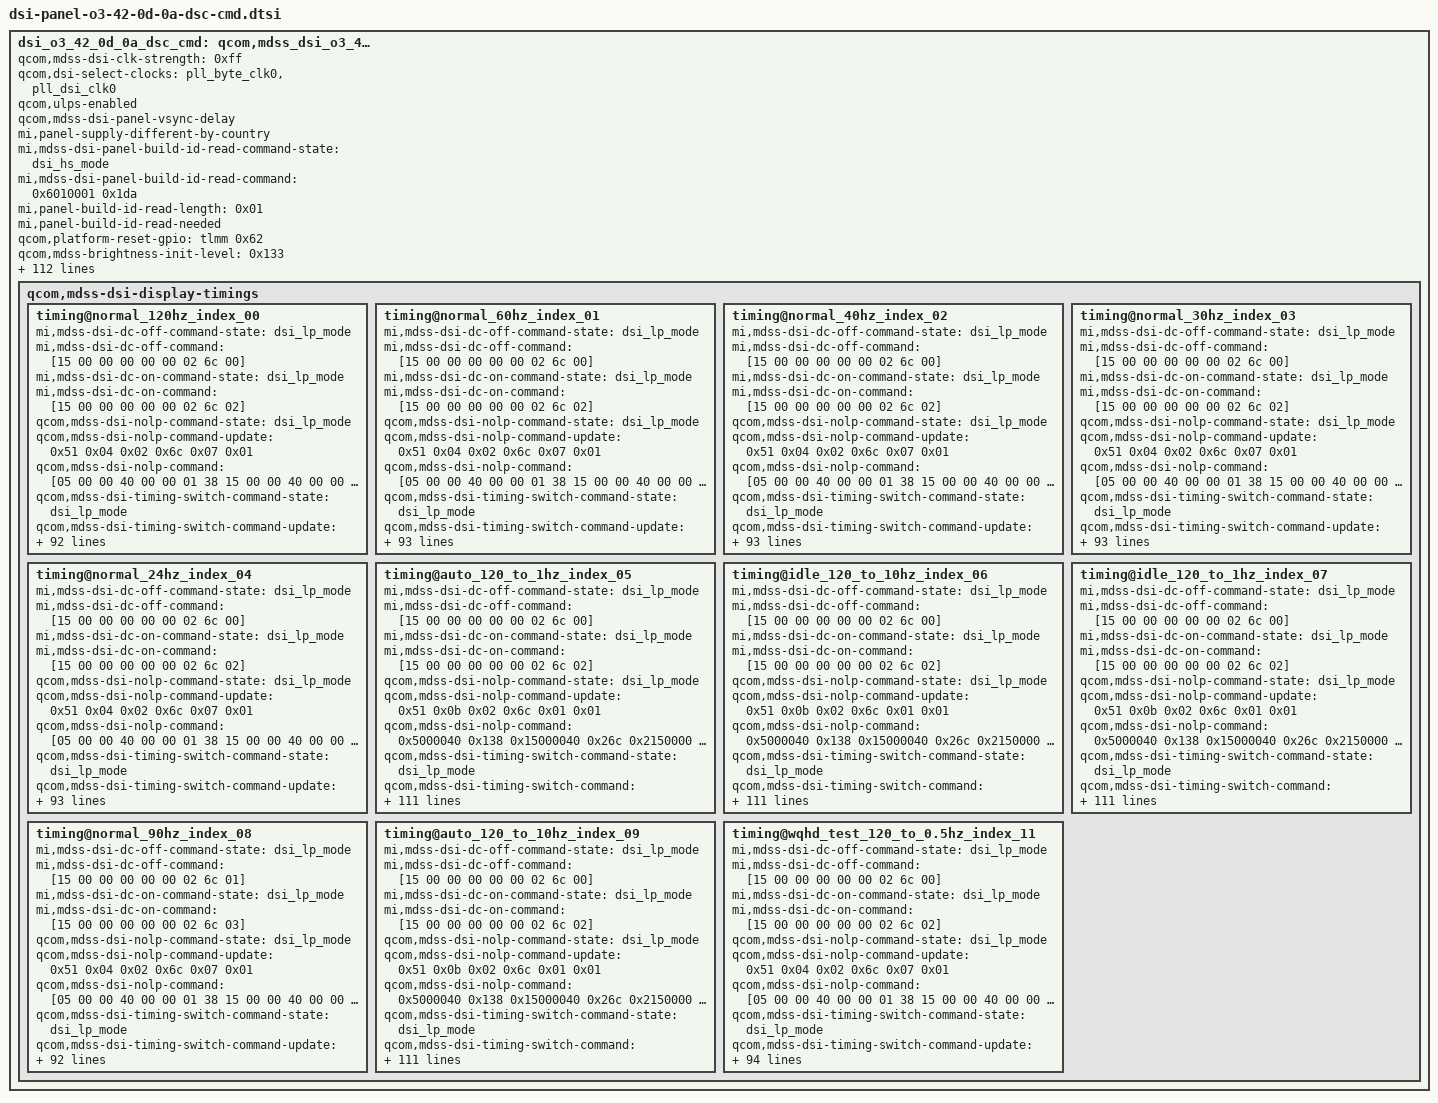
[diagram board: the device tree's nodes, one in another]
// SPDX-License-Identifier: BSD-3-Clause
/*
 * Copyright (c) 2023-2024 Qualcomm Innovation Center, Inc. All rights reserved.
 * Copyright (c) 2025 The LineageOS Project
 */

dsi_o3_42_0d_0a_dsc_cmd: qcom,mdss_dsi_o3_42_0d_0a_dsc_cmd {
	qcom,mdss-dsi-clk-strength = <0xff>;
	qcom,dsi-select-clocks = "pll_byte_clk0", "pll_dsi_clk0";
	qcom,ulps-enabled;
	qcom,mdss-dsi-panel-vsync-delay;
	mi,panel-supply-different-by-country;
	mi,mdss-dsi-panel-build-id-read-command-state = "dsi_hs_mode";
	mi,mdss-dsi-panel-build-id-read-command = <0x6010001 0x1da>;
	mi,panel-build-id-read-length = <0x01>;
	mi,panel-build-id-read-needed;
	qcom,platform-reset-gpio = <&tlmm 0x62 0x00>;
	qcom,mdss-brightness-init-level = <0x133>;
	qcom,mdss-brightness-max-level = <0x1fff>;
	qcom,bl-dsc-cmd-state = "dsi_hs_mode";
	qcom,mdss-dsi-bl-max-level = <0x1fff>;
	qcom,mdss-dsi-bl-min-level = <0x19>;
	qcom,mdss-dsi-bl-pmic-control-type = "bl_ctrl_dcs";
	qcom,panel-global-supply-entries = <&dsi_panel_pwr_supply_O3GL>;
	qcom,panel-supply-entries = <&dsi_panel_pwr_supply_O3>;
	qcom,mdss-disable-cesta-hw-sleep;
	mi,ddic-round-corner-enabled;
	mi,dc-feature-enabled;
	mi,doze-lbm-dbv-level = <0x12>;
	mi,doze-hbm-dbv-level = <0xcf>;
	mi,mdss-dsi-panel-flatmode-on-status-value = <0x71>;
	mi,mdss-dsi-panel-flatmode-status-read-length = <0x01>;
	mi,mdss-dsi-panel-flatmode-status-command-state = "dsi_hs_mode";
	mi,mdss-dsi-panel-flatmode-status-command = <0x6010001 0x1d5>;
	mi,mdss-dsi-panel-flatmode-status-offset-command-state = "dsi_hs_mode";
	mi,mdss-dsi-panel-flatmode-status-offset-command = [39 00 00 00 00 00 03 f0 aa 11];
	mi,flatmode-status-check-enabled;
	mi,mdss-fac-brightness-max-level = <0xaab>;
	mi,mdss-dsi-fac-bl-max-level = <0xaab>;
	qcom,mdss-dsi-panel-status-read-length = <0x01 0x03>;
	qcom,mdss-dsi-panel-status-value = <0x08 0x12 0x00 0x00>;
	mi,mdss-dsi-panel-status-after-command-state = "dsi_lp_mode";
	mi,mdss-dsi-panel-status-offset-command-state = "dsi_lp_mode";
	qcom,mdss-dsi-panel-status-command-state = "dsi_lp_mode";
	mi,mdss-dsi-panel-status-after-command = <0x39000000 0x3ff 0x5a003900 0x00 0x3f0aa00>;
	qcom,mdss-dsi-panel-status-command = <0x6010000 0x1f9 0x6010000 0x170>;
	mi,mdss-dsi-panel-status-offset-command = [39 00 00 00 00 00 03 ff 5a 82 39 00 00 00 00 00 02 65 01];
	qcom,mdss-dsi-panel-status-check-mode = "reg_read";
	mi,mdss-dsi-panel-status-check-interval = <0x1388>;
	qcom,esd-aod-check-enabled;
	qcom,esd-check-enabled;
	mi,mdss-dsi-panel-cell-id-read-length = <0x0d>;
	mi,mdss-dsi-panel-cell-id-read-command-state = "dsi_hs_mode";
	mi,mdss-dsi-panel-cell-id-read-command = <0x6010001 0x15a>;
	mi,mdss-dsi-panel-wp-read-length = <0x08>;
	mi,mdss-dsi-panel-wp-read-command-state = "dsi_hs_mode";
	mi,mdss-dsi-panel-wp-read-command = <0x6010001 0x15c>;
	qcom,spr-pentile-pack-type = "RG-BG Type A";
	qcom,spr-pack-type = "pentile";
	mi,esd-err-irq-gpio-flag = <0x2004>;
	mi,esd-err-irq-gpio = <&tlmm 0x57 0x2004>;
	mi,need-update-gamma-befor-init;
	mi,max-brightness-clone = <0x3fff>;
	mi,panel-on-dimming-delay = <0x78>;
	mi,panel-id = <0x4f33 0x420d0a>;
	qcom,mdss-dsi-dma-schedule-window = <0x32>;
	qcom,mdss-dsi-dma-schedule-line = <0x01>;
	qcom,bl-update-flag = "delay_until_first_frame";
	qcom,mdss-dsi-bl-inverted-dbv;
	qcom,mdss-dsi-panel-blackness-level = <0xc9e>;
	qcom,mdss-dsi-panel-peak-brightness = <0x1e84800>;
	qcom,mdss-dsi-panel-hdr-color-primaries = <0x38a4 0x3c8c 0x7d00 0x4268 0x3c8c 0x7530 0x1f40 0xbb8>;
	qcom,mdss-dsi-panel-hdr-enabled;
	qcom,mdss-dsi-lp11-init;
	qcom,mdss-dsi-tx-eot-append;
	qcom,mdss-dsi-te-using-te-pin;
	qcom,mdss-dsi-te-check-enable;
	qcom,mdss-dsi-te-dcs-command = <0x01>;
	qcom,mdss-dsi-wr-mem-continue = <0x3c>;
	qcom,mdss-dsi-wr-mem-start = <0x2c>;
	qcom,mdss-dsi-te-pin-select = <0x01>;
	qcom,mdss-pan-physical-height-dimension = <0x5c1>;
	qcom,mdss-pan-physical-width-dimension = <0x297>;
	qcom,mdss-dsi-reset-sequence = <0x00 0x0f 0x01 0x19>;
	qcom,mdss-dsi-mdp-trigger = "none";
	qcom,mdss-dsi-dma-trigger = "trigger_sw";
	qcom,mdss-dsi-lane-3-state;
	qcom,mdss-dsi-lane-2-state;
	qcom,mdss-dsi-lane-1-state;
	qcom,mdss-dsi-lane-0-state;
	qcom,mdss-dsi-bllp-power-mode;
	qcom,mdss-dsi-bllp-eof-power-mode;
	qcom,mdss-dsi-lane-map = "lane_map_0123";
	qcom,mdss-dsi-traffic-mode = "burst_mode";
	qcom,dsi-phy-num = <0x00>;
	qcom,dsi-ctrl-num = <0x00>;
	qcom,mdss-dsi-border-color = <0x00>;
	qcom,mdss-dsi-underflow-color = <0xff>;
	qcom,mdss-dsi-color-order = "rgb_swap_rgb";
	qcom,mdss-dsi-bpp = <0x1e>;
	qcom,mdss-dsi-stream = <0x00>;
	qcom,mdss-dsi-virtual-channel-id = <0x00>;
	qcom,mdss-dsi-panel-type = "dsi_cmd_mode";
	qcom,mdss-dsi-panel-name = "xiaomi o3 42 0d 0a cmd mode dsc dsi panel";

	qcom,mdss-dsi-display-timings {

		timing@normal_120hz_index_00 {
			mi,mdss-dsi-dc-off-command-state = "dsi_lp_mode";
			mi,mdss-dsi-dc-off-command = [15 00 00 00 00 00 02 6c 00];
			mi,mdss-dsi-dc-on-command-state = "dsi_lp_mode";
			mi,mdss-dsi-dc-on-command = [15 00 00 00 00 00 02 6c 02];
			qcom,mdss-dsi-nolp-command-state = "dsi_lp_mode";
			qcom,mdss-dsi-nolp-command-update = <0x51 0x04 0x02 0x6c 0x07 0x01>;
			qcom,mdss-dsi-nolp-command = [05 00 00 40 00 00 01 38 15 00 00 40 00 00 02 75 00 39 00 00 40 00 00 03 f0 aa 1b 15 00 00 40 00 00 02 d0 00 39 00 00 40 00 00 03 51 00 00 39 00 00 40 00 00 03 f0 aa 10 15 00 00 00 09 00 02 cf 16 15 00 00 40 00 00 02 6c 02 15 00 00 40 00 00 02 71 00 39 00 00 00 00 00 03 f0 aa 00];
			qcom,mdss-dsi-timing-switch-command-state = "dsi_lp_mode";
			qcom,mdss-dsi-timing-switch-command-update = <0x6c 0x03 0x01>;
			qcom,mdss-dsi-timing-switch-command = [39 00 00 40 00 00 03 f0 aa 1b 15 00 00 40 00 00 02 d0 00 15 00 00 00 00 00 02 75 00 15 00 00 40 00 00 02 6c 02 15 00 00 00 00 00 02 71 00];
			qcom,mdss-dsi-on-command-state = "dsi_lp_mode";
			qcom,mdss-dsi-on-command = <0x39000040 0x3f0 0xaa101500 0x400000 0x2650115 0x4000 0x2d005 0x15000040 0x203 0x1150000 0x40000002 0x35001500 0x400000 0x2532839 0x4000 0x3f0aa 0x13150000 0x40000002 0xc8101500 0x400000 0x2d01015 0x4000 0x2e010 0x15000040 0x2e8 0x10390000 0x40000003 0x51000015 0x4000 0x25e00 0x15000040 0x259 0x9390000 0x40000003 0xff5a8115 0x4000 0x2651b 0x15000040 0x2f8 0x4150000 0x40000002 0x651a1500 0x400000 0x2f80f15 0x4000 0x2650a 0x15000000 0x2f8 0xfb390000 0x40000003 0xf0aa1b15 0x4000 0x2d000 0x15000000 0x275 0x150000 0x40000002 0x71001500 0x400000 0x26c0239 0x4000 0x3f0aa 0x10150000 0x02 0xcf091500 0x400000 0x26d0015 0x4000 0x26f02 0x15000040 0x272 0x390000 0x60 0x70120000 0xab21000a 0x6e04b000 0x1e025802 0x58015501 0xd2000a01 0x88003200 0xd039711 0x4808000c 0x71020 0x60f0f 0x330e1c2a 0x38465462 0x69707779 0x7b7d7e00 0x82114019 0xc0223e32 0x7c3aba3a 0xf83b383b 0x383b764b 0x764b744b 0x745bb473 0xf4010000 0x00 0x39000040 0x3f0 0xaa103900 0x400000 0xebd1002 0x3146758a 0xb9013245 0x7689ba39 0x4000 0x3f0aa 0x17150000 0x40000002 0xb0113900 0x400000 0x7c02100 0x34203104 0x15000040 0x265 0x6150000 0x40000002 0xbfff3900 0x400000 0x3ff5a80 0x15000040 0x265 0xa390000 0x40000003 0xf99e8f15 0x4000 0x2650f 0x15000040 0x2f9 0x14390000 0x40000003 0xff5a8115 0x4000 0x26503 0x15000040 0x2f3 0x24150000 0x40000002 0x65051500 0x400000 0x2f3a039 0x4000 0x3ff5a 0x81150000 0x40000002 0x65023900 0x400000 0x5fbd3d3 0xd3d33900 0x400000 0x3f0aa10 0x15000040 0x265 0x4150000 0x02 0xcf4b3900 0x400000 0x3f0aa10 0x15000040 0x265 0x1150000 0x02 0xcf073900 0x400000 0x3f0aa10 0x15000040 0x265 0x3150000 0x02 0xcf243900 0x400000 0x3f0aa10 0x15000040 0x2b6 0x390000 0x40000003 0xff5a8215 0x4000 0x26504 0x15000000 0x2f8 0x10390000 0x40000003 0xf0aa1115 0x4000 0x2c000 0x15000040 0x265 0x9390000 0x40000004 0xc055aaaa 0x39000040 0xcc1 0x3340399 0x33403ff 0xffa60015 0x4000 0x25501 0x39000040 0x3f0 0xaa101500 0x400000 0x2650715 0x4000 0x2d000 0x15000040 0x265 0x9390000 0x40000003 0xd0031915 0x4000 0x2650c 0x15000040 0x2d0 0x150000 0x40000002 0x650e3900 0x400000 0x3d00319 0x15000040 0x265 0x11150000 0x40000002 0xd0193900 0x400000 0x3f0aa12 0x15000040 0x265 0xb150000 0x40000002 0xd2103900 0x400000 0x3f0aa10 0x39000000 0x9c4 0x34343434 0x34343434 0x39000040 0x3f0 0xaa121500 0x400000 0x2d60015 0x4000 0x26502 0x15000000 0x2d1 0x390000 0x40000003 0x5f047e39 0x4000 0x3f0aa 0x12390000 0x40000020 0xc3e12030 0x1cd01cd 0x1cd01cd 0x1cd01cd 0x1cd0064 0x640064 0x640064 0x640064 0x39000040 0x3ff 0x5a811500 0x400000 0x2651515 0x00 0x2fc7e 0x5000000 0x78000111 0x5000000 0x129>;
			qcom,dsi-mode-te-width-us = <245>;
			mi,mdss-dc-status-control-dc-6C-cfg = <0x02 0x00>;
			qcom,mdss-dsi-h-sync-skew = <0x00>;
			qcom,mdss-dsi-panel-framerate = <0x78>;
			cell-index = <0x00>;
			qcom,src-chroma-format = <0x01>;
			qcom,mdss-dsc-block-prediction-enable;
			qcom,mdss-dsc-bit-per-pixel = <0x08>;
			qcom,mdss-dsc-bit-per-component = <0x0a>;
			qcom,mdss-dsc-slice-per-pkt = <0x02>;
			qcom,mdss-dsc-slice-width = <0x258>;
			qcom,mdss-dsc-slice-height = <0x1e>;
			qcom,mdss-dsc-scr-version = <0x00>;
			qcom,mdss-dsc-version = <0x12>;
			qcom,compression-mode = "dsc";
			qcom,default-topology-index = <0x00>;
			qcom,display-topology = <0x02 0x02 0x01>;
			qcom,mdss-dsi-panel-phy-timings = [00 26 0a 0a 1b 19 0a 0a 0a 02 04 00 20 0f];
			qcom,mdss-mdp-transfer-time-us = <7300>;
			qcom,mdss-dsi-panel-jitter = <0x05 0x01>;
			qcom,mdss-dsi-panel-clockrate = <0x448b9b80>;
			qcom,mdss-dsi-v-bottom-border = <0x00>;
			qcom,mdss-dsi-v-top-border = <0x00>;
			qcom,mdss-dsi-h-right-border = <0x00>;
			qcom,mdss-dsi-h-left-border = <0x00>;
			qcom,mdss-dsi-h-sync-pulse = <0x00>;
			qcom,mdss-dsi-v-pulse-width = <0x08>;
			qcom,mdss-dsi-v-front-porch = <0x2d>;
			qcom,mdss-dsi-v-back-porch = <0x25>;
			qcom,mdss-dsi-h-pulse-width = <0x10>;
			qcom,mdss-dsi-h-back-porch = <0x20>;
			qcom,mdss-dsi-h-front-porch = <0x10>;
			qcom,mdss-dsi-panel-height = <0xa6e>;
			qcom,mdss-dsi-panel-width = <0x4b0>;
			mi,mdss-dsi-dimmingoff-command-state = "dsi_hs_mode";
			mi,mdss-dsi-dimmingoff-command = [15 00 00 00 00 00 02 53 20];
			mi,mdss-dsi-dimmingon-command-state = "dsi_hs_mode";
			mi,mdss-dsi-dimmingon-command = [15 00 00 00 00 00 02 53 28];
			mi,mdss-dsi-auto-current-limit-command-update = <0xc1 0x01 0x02>;
			mi,mdss-dsi-auto-current-limit-command-state = "dsi_lp_mode";
			mi,mdss-dsi-auto-current-limit-command = <0x39000040 0x3f0 0xaa113900 0x00 0x3c103ff>;
			mi,mdss-dsi-round-corner-off-command-state = "dsi_lp_mode";
			mi,mdss-dsi-round-corner-off-command = [39 00 00 40 00 00 03 f0 aa 18 15 00 00 00 00 00 02 b0 00];
			mi,mdss-dsi-round-corner-on-command-state = "dsi_lp_mode";
			mi,mdss-dsi-round-corner-on-command = [39 00 00 40 00 00 03 f0 aa 18 15 00 00 00 00 00 02 b0 80];
			mi,mdss-dsi-doze-lbm-nolp-command-state = "dsi_lp_mode";
			mi,mdss-dsi-doze-hbm-nolp-command-state = "dsi_lp_mode";
			mi,mdss-dsi-doze-lbm-nolp-command = [05 00 00 40 00 00 01 38 15 00 00 40 00 00 02 75 00 39 00 00 40 00 00 03 f0 aa 1b 15 00 00 40 00 00 02 d0 00 39 00 00 40 00 00 03 51 00 14 39 00 00 40 00 00 03 f0 aa 10 15 00 00 00 00 00 02 cf 16];
			mi,mdss-dsi-doze-hbm-nolp-command = [05 00 00 40 00 00 01 38 15 00 00 40 00 00 02 75 00 39 00 00 40 00 00 03 f0 aa 1b 15 00 00 40 00 00 02 d0 00 39 00 00 40 00 00 03 51 00 ee 39 00 00 40 00 00 03 f0 aa 10 15 00 00 00 00 00 02 cf 16];
			mi,mdss-dsi-doze-lbm-command-state = "dsi_lp_mode";
			mi,mdss-dsi-doze-lbm-command = [39 00 00 40 00 00 03 f0 aa 1b 15 00 00 40 00 00 02 d0 00 15 00 00 40 00 00 02 75 00 15 00 00 00 09 00 02 71 00 39 00 00 40 00 00 03 f0 aa 1b 39 00 00 40 00 00 0e d2 04 01 03 04 0b 0b 0b 0b 0b 00 0e e0 00 15 00 00 40 00 00 02 d0 11 05 00 00 40 00 00 01 39 15 00 00 40 00 00 02 6d 02 15 00 00 40 00 00 02 75 01 39 00 00 40 00 00 03 f0 aa 10 15 00 00 40 00 00 02 cf 09 15 00 00 40 00 00 02 53 20 39 00 00 00 00 00 03 51 00 12];
			mi,mdss-dsi-doze-hbm-command-state = "dsi_lp_mode";
			mi,mdss-dsi-doze-hbm-command = [39 00 00 40 00 00 03 f0 aa 1b 15 00 00 40 00 00 02 d0 00 15 00 00 40 00 00 02 75 00 15 00 00 00 09 00 02 71 00 39 00 00 40 00 00 03 f0 aa 1b 39 00 00 40 00 00 0e d2 04 01 03 04 0b 0b 0b 0b 0b 00 0e e0 00 15 00 00 40 00 00 02 d0 11 05 00 00 40 00 00 01 39 15 00 00 40 00 00 02 6d 00 15 00 00 40 00 00 02 75 01 39 00 00 40 00 00 03 f0 aa 10 15 00 00 40 00 00 02 cf 09 15 00 00 40 00 00 02 53 20 39 00 00 00 00 00 03 51 00 cf];
			mi,mdss-dsi-hbm-off-command-state = "dsi_hs_mode";
			mi,mdss-dsi-hbm-off-command = [39 00 00 40 00 00 03 f0 aa 10 15 00 00 40 00 00 02 65 01 15 00 00 40 00 00 02 d0 04 39 00 00 00 00 00 03 51 0a ab];
			mi,mdss-dsi-hbm-on-command-state = "dsi_hs_mode";
			mi,mdss-dsi-hbm-on-command = [39 00 00 40 00 00 03 f0 aa 10 15 00 00 40 00 00 02 65 01 15 00 00 40 00 00 02 d0 05 39 00 00 00 00 00 03 51 17 ff];
			mi,mdss-dsi-vint-off-command-state = "dsi_lp_mode";
			mi,mdss-dsi-vint-off-command = [39 00 00 40 00 00 03 f0 aa 12 39 00 00 40 00 00 02 bf 63 39 00 00 40 00 00 02 65 30 39 00 00 40 00 00 02 bf 63 39 00 00 40 00 00 02 d9 63 39 00 00 40 00 00 02 65 30 39 00 00 40 00 00 02 d9 63 39 00 00 40 00 00 02 df 63 39 00 00 40 00 00 02 65 30 39 00 00 40 00 00 02 df 63 39 00 00 40 00 00 02 eb 63 39 00 00 40 00 00 02 65 30 39 00 00 00 00 00 02 eb 63];
			qcom,mdss-dsi-off-command-state = "dsi_hs_mode";
			qcom,mdss-dsi-off-command = <0x5000000 0x128 0x5000000 0x78000110>;
		};

		timing@normal_60hz_index_01 {
			mi,mdss-dsi-dc-off-command-state = "dsi_lp_mode";
			mi,mdss-dsi-dc-off-command = [15 00 00 00 00 00 02 6c 00];
			mi,mdss-dsi-dc-on-command-state = "dsi_lp_mode";
			mi,mdss-dsi-dc-on-command = [15 00 00 00 00 00 02 6c 02];
			qcom,mdss-dsi-nolp-command-state = "dsi_lp_mode";
			qcom,mdss-dsi-nolp-command-update = <0x51 0x04 0x02 0x6c 0x07 0x01>;
			qcom,mdss-dsi-nolp-command = [05 00 00 40 00 00 01 38 15 00 00 40 00 00 02 75 00 39 00 00 40 00 00 03 f0 aa 1b 15 00 00 40 00 00 02 d0 00 39 00 00 40 00 00 03 51 00 00 39 00 00 40 00 00 03 f0 aa 10 15 00 00 00 09 00 02 cf 16 15 00 00 40 00 00 02 6c 02 39 00 00 40 00 00 04 71 01 01 00 39 00 00 00 00 00 03 f0 aa 00];
			qcom,mdss-dsi-timing-switch-command-state = "dsi_lp_mode";
			qcom,mdss-dsi-timing-switch-command-update = <0x6c 0x03 0x01>;
			qcom,mdss-dsi-timing-switch-command = [39 00 00 40 00 00 03 f0 aa 1b 15 00 00 40 00 00 02 d0 00 15 00 00 00 00 00 02 75 00 15 00 00 40 00 00 02 6c 02 39 00 00 40 00 00 04 71 01 01 00 39 00 00 40 00 00 03 f0 aa 10 15 00 00 00 00 00 02 cf 16];
			qcom,mdss-dsi-on-command-state = "dsi_lp_mode";
			qcom,mdss-dsi-on-command = [39 00 00 40 00 00 03 f0 aa 10 15 00 00 40 00 00 02 65 01 15 00 00 40 00 00 02 d0 05 15 00 00 40 00 00 02 03 01 15 00 00 40 00 00 02 35 00 15 00 00 40 00 00 02 53 28 39 00 00 40 00 00 03 f0 aa 13 15 00 00 40 00 00 02 c8 10 15 00 00 40 00 00 02 d0 10 15 00 00 40 00 00 02 e0 10 15 00 00 40 00 00 02 e8 10 39 00 00 40 00 00 03 51 00 00 15 00 00 40 00 00 02 5e 00 15 00 00 40 00 00 02 59 09 39 00 00 40 00 00 03 ff 5a 81 15 00 00 40 00 00 02 65 1b 15 00 00 40 00 00 02 f8 04 15 00 00 40 00 00 02 65 1a 15 00 00 40 00 00 02 f8 0f 15 00 00 40 00 00 02 65 0a 15 00 00 00 00 00 02 f8 fb 39 00 00 40 00 00 03 f0 aa 1b 15 00 00 40 00 00 02 d0 00 15 00 00 00 00 00 02 75 00 15 00 00 40 00 00 02 6c 02 39 00 00 40 00 00 04 71 01 01 00 39 00 00 40 00 00 03 f0 aa 10 15 00 00 00 00 00 02 cf 16 15 00 00 40 00 00 02 6d 00 15 00 00 40 00 00 02 6f 02 15 00 00 40 00 00 02 72 00 39 00 00 00 00 00 60 70 12 00 00 ab 21 00 0a 6e 04 b0 00 1e 02 58 02 58 01 55 01 d2 00 0a 01 88 00 32 00 0d 03 97 11 48 08 00 0c 00 07 10 20 00 06 0f 0f 33 0e 1c 2a 38 46 54 62 69 70 77 79 7b 7d 7e 00 82 11 40 19 c0 22 3e 32 7c 3a ba 3a f8 3b 38 3b 38 3b 76 4b 76 4b 74 4b 74 5b b4 73 f4 01 00 00 00 00 00 00 39 00 00 40 00 00 03 f0 aa 10 39 00 00 40 00 00 0e bd 10 02 31 46 75 8a b9 01 32 45 76 89 ba 39 00 00 40 00 00 03 f0 aa 17 15 00 00 40 00 00 02 b0 11 39 00 00 40 00 00 07 c0 21 00 34 20 31 04 15 00 00 40 00 00 02 65 06 15 00 00 40 00 00 02 bf ff 39 00 00 40 00 00 03 ff 5a 80 15 00 00 40 00 00 02 65 0a 39 00 00 40 00 00 03 f9 9e 8f 15 00 00 40 00 00 02 65 0f 15 00 00 40 00 00 02 f9 14 39 00 00 40 00 00 03 ff 5a 81 15 00 00 40 00 00 02 65 03 15 00 00 40 00 00 02 f3 24 15 00 00 40 00 00 02 65 05 15 00 00 40 00 00 02 f3 a0 39 00 00 40 00 00 03 ff 5a 81 15 00 00 40 00 00 02 65 02 39 00 00 40 00 00 05 fb d3 d3 d3 d3 39 00 00 40 00 00 03 f0 aa 10 15 00 00 40 00 00 02 65 04 15 00 00 00 00 00 02 cf 4b 39 00 00 40 00 00 03 f0 aa 10 15 00 00 40 00 00 02 65 01 15 00 00 00 00 00 02 cf 07 39 00 00 40 00 00 03 f0 aa 10 15 00 00 40 00 00 02 65 03 15 00 00 00 00 00 02 cf 24 39 00 00 40 00 00 03 f0 aa 10 15 00 00 40 00 00 02 b6 00 39 00 00 40 00 00 03 ff 5a 82 15 00 00 40 00 00 02 65 04 15 00 00 00 00 00 02 f8 10 39 00 00 40 00 00 03 f0 aa 11 15 00 00 40 00 00 02 c0 00 15 00 00 40 00 00 02 65 09 39 00 00 40 00 00 04 c0 55 aa aa 39 00 00 40 00 00 0c c1 03 34 03 99 03 34 03 ff ff a6 00 15 00 00 40 00 00 02 55 01 39 00 00 40 00 00 03 f0 aa 10 15 00 00 40 00 00 02 65 07 15 00 00 40 00 00 02 d0 00 15 00 00 40 00 00 02 65 09 39 00 00 40 00 00 03 d0 03 19 15 00 00 40 00 00 02 65 0c 15 00 00 40 00 00 02 d0 00 15 00 00 40 00 00 02 65 0e 39 00 00 40 00 00 03 d0 03 19 15 00 00 40 00 00 02 65 11 15 00 00 40 00 00 02 d0 19 39 00 00 40 00 00 03 f0 aa 12 15 00 00 40 00 00 02 65 0b 15 00 00 40 00 00 02 d2 10 39 00 00 40 00 00 03 f0 aa 10 39 00 00 00 00 00 09 c4 34 34 34 34 34 34 34 34 39 00 00 40 00 00 03 f0 aa 12 15 00 00 40 00 00 02 d6 00 15 00 00 40 00 00 02 65 02 15 00 00 00 00 00 02 d1 00 39 00 00 40 00 00 03 5f 04 7e 39 00 00 40 00 00 03 f0 aa 12 39 00 00 40 00 00 20 c3 e1 20 30 01 cd 01 cd 01 cd 01 cd 01 cd 01 cd 01 cd 00 64 00 64 00 64 00 64 00 64 00 64 00 64 39 00 00 40 00 00 03 ff 5a 81 15 00 00 40 00 00 02 65 15 15 00 00 00 00 00 02 fc 7e 05 00 00 00 78 00 01 11 05 00 00 00 00 00 01 29];
			qcom,dsi-mode-te-width-us = <8567>;
			qcom,disable-rsc-solver;
			mi,mdss-dc-status-control-dc-6C-cfg = <0x02 0x00>;
			qcom,mdss-dsi-h-sync-skew = <0x00>;
			qcom,mdss-dsi-panel-framerate = <0x3c>;
			cell-index = <0x01>;
			qcom,src-chroma-format = <0x01>;
			qcom,mdss-dsc-block-prediction-enable;
			qcom,mdss-dsc-bit-per-pixel = <0x08>;
			qcom,mdss-dsc-bit-per-component = <0x0a>;
			qcom,mdss-dsc-slice-per-pkt = <0x02>;
			qcom,mdss-dsc-slice-width = <0x258>;
			qcom,mdss-dsc-slice-height = <0x1e>;
			qcom,mdss-dsc-scr-version = <0x00>;
			qcom,mdss-dsc-version = <0x12>;
			qcom,compression-mode = "dsc";
			qcom,default-topology-index = <0x00>;
			qcom,display-topology = <0x02 0x02 0x01>;
			qcom,mdss-dsi-panel-phy-timings = [00 26 0a 0a 1b 19 0a 0a 0a 02 04 00 20 0f];
			qcom,mdss-mdp-transfer-time-us = <7300>;
			qcom,mdss-dsi-panel-jitter = <0x05 0x01>;
			qcom,mdss-dsi-panel-clockrate = <0x448b9b80>;
			qcom,mdss-dsi-v-bottom-border = <0x00>;
			qcom,mdss-dsi-v-top-border = <0x00>;
			qcom,mdss-dsi-h-right-border = <0x00>;
			qcom,mdss-dsi-h-left-border = <0x00>;
			qcom,mdss-dsi-h-sync-pulse = <0x00>;
			qcom,mdss-dsi-v-pulse-width = <0x08>;
			qcom,mdss-dsi-v-front-porch = <0x2d>;
			qcom,mdss-dsi-v-back-porch = <0x25>;
			qcom,mdss-dsi-h-pulse-width = <0x10>;
			qcom,mdss-dsi-h-back-porch = <0x20>;
			qcom,mdss-dsi-h-front-porch = <0x10>;
			qcom,mdss-dsi-panel-height = <0xa6e>;
			qcom,mdss-dsi-panel-width = <0x4b0>;
			mi,mdss-dsi-dimmingoff-command-state = "dsi_hs_mode";
			mi,mdss-dsi-dimmingoff-command = [15 00 00 00 00 00 02 53 20];
			mi,mdss-dsi-dimmingon-command-state = "dsi_hs_mode";
			mi,mdss-dsi-dimmingon-command = [15 00 00 00 00 00 02 53 28];
			mi,mdss-dsi-auto-current-limit-command-update = <0xc1 0x01 0x02>;
			mi,mdss-dsi-auto-current-limit-command-state = "dsi_lp_mode";
			mi,mdss-dsi-auto-current-limit-command = <0x39000040 0x3f0 0xaa113900 0x00 0x3c103ff>;
			mi,mdss-dsi-round-corner-off-command-state = "dsi_lp_mode";
			mi,mdss-dsi-round-corner-off-command = [39 00 00 40 00 00 03 f0 aa 18 15 00 00 00 00 00 02 b0 00];
			mi,mdss-dsi-round-corner-on-command-state = "dsi_lp_mode";
			mi,mdss-dsi-round-corner-on-command = [39 00 00 40 00 00 03 f0 aa 18 15 00 00 00 00 00 02 b0 80];
			mi,mdss-dsi-doze-lbm-nolp-command-state = "dsi_lp_mode";
			mi,mdss-dsi-doze-hbm-nolp-command-state = "dsi_lp_mode";
			mi,mdss-dsi-doze-lbm-nolp-command = [05 00 00 40 00 00 01 38 15 00 00 40 00 00 02 75 00 39 00 00 40 00 00 03 f0 aa 1b 15 00 00 40 00 00 02 d0 00 39 00 00 40 00 00 03 51 00 14 39 00 00 40 00 00 03 f0 aa 10 15 00 00 00 00 00 02 cf 16];
			mi,mdss-dsi-doze-hbm-nolp-command = [05 00 00 40 00 00 01 38 15 00 00 40 00 00 02 75 00 39 00 00 40 00 00 03 f0 aa 1b 15 00 00 40 00 00 02 d0 00 39 00 00 40 00 00 03 51 00 ee 39 00 00 40 00 00 03 f0 aa 10 15 00 00 00 00 00 02 cf 16];
			mi,mdss-dsi-doze-lbm-command-state = "dsi_lp_mode";
			mi,mdss-dsi-doze-lbm-command = [39 00 00 40 00 00 03 f0 aa 1b 15 00 00 40 00 00 02 d0 00 15 00 00 40 00 00 02 75 00 15 00 00 00 09 00 02 71 00 39 00 00 40 00 00 03 f0 aa 1b 39 00 00 40 00 00 0e d2 04 01 03 04 0b 0b 0b 0b 0b 00 0e e0 00 15 00 00 40 00 00 02 d0 11 05 00 00 40 00 00 01 39 15 00 00 40 00 00 02 6d 02 15 00 00 40 00 00 02 75 01 39 00 00 40 00 00 03 f0 aa 10 15 00 00 40 00 00 02 cf 09 15 00 00 40 00 00 02 53 20 39 00 00 00 00 00 03 51 00 12];
			mi,mdss-dsi-doze-hbm-command-state = "dsi_lp_mode";
			mi,mdss-dsi-doze-hbm-command = [39 00 00 40 00 00 03 f0 aa 1b 15 00 00 40 00 00 02 d0 00 15 00 00 40 00 00 02 75 00 15 00 00 00 09 00 02 71 00 39 00 00 40 00 00 03 f0 aa 1b 39 00 00 40 00 00 0e d2 04 01 03 04 0b 0b 0b 0b 0b 00 0e e0 00 15 00 00 40 00 00 02 d0 11 05 00 00 40 00 00 01 39 15 00 00 40 00 00 02 6d 00 15 00 00 40 00 00 02 75 01 39 00 00 40 00 00 03 f0 aa 10 15 00 00 40 00 00 02 cf 09 15 00 00 40 00 00 02 53 20 39 00 00 00 00 00 03 51 00 cf];
			mi,mdss-dsi-hbm-off-command-state = "dsi_hs_mode";
			mi,mdss-dsi-hbm-off-command = [39 00 00 40 00 00 03 f0 aa 10 15 00 00 40 00 00 02 65 01 15 00 00 40 00 00 02 d0 04 39 00 00 00 00 00 03 51 0a ab];
			mi,mdss-dsi-hbm-on-command-state = "dsi_hs_mode";
			mi,mdss-dsi-hbm-on-command = [39 00 00 40 00 00 03 f0 aa 10 15 00 00 40 00 00 02 65 01 15 00 00 40 00 00 02 d0 05 39 00 00 00 00 00 03 51 17 ff];
			mi,mdss-dsi-vint-off-command-state = "dsi_lp_mode";
			mi,mdss-dsi-vint-off-command = [39 00 00 40 00 00 03 f0 aa 12 39 00 00 40 00 00 02 bf 63 39 00 00 40 00 00 02 65 30 39 00 00 40 00 00 02 bf 63 39 00 00 40 00 00 02 d9 63 39 00 00 40 00 00 02 65 30 39 00 00 40 00 00 02 d9 63 39 00 00 40 00 00 02 df 63 39 00 00 40 00 00 02 65 30 39 00 00 40 00 00 02 df 63 39 00 00 40 00 00 02 eb 63 39 00 00 40 00 00 02 65 30 39 00 00 00 00 00 02 eb 63];
			qcom,mdss-dsi-off-command-state = "dsi_hs_mode";
			qcom,mdss-dsi-off-command = <0x5000000 0x128 0x5000000 0x78000110>;
		};

		timing@normal_40hz_index_02 {
			mi,mdss-dsi-dc-off-command-state = "dsi_lp_mode";
			mi,mdss-dsi-dc-off-command = [15 00 00 00 00 00 02 6c 00];
			mi,mdss-dsi-dc-on-command-state = "dsi_lp_mode";
			mi,mdss-dsi-dc-on-command = [15 00 00 00 00 00 02 6c 02];
			qcom,mdss-dsi-nolp-command-state = "dsi_lp_mode";
			qcom,mdss-dsi-nolp-command-update = <0x51 0x04 0x02 0x6c 0x07 0x01>;
			qcom,mdss-dsi-nolp-command = [05 00 00 40 00 00 01 38 15 00 00 40 00 00 02 75 00 39 00 00 40 00 00 03 f0 aa 1b 15 00 00 40 00 00 02 d0 00 39 00 00 40 00 00 03 51 00 00 39 00 00 40 00 00 03 f0 aa 10 15 00 00 00 09 00 02 cf 16 15 00 00 40 00 00 02 6c 02 39 00 00 40 00 00 04 71 01 02 00 39 00 00 00 00 00 03 f0 aa 00];
			qcom,mdss-dsi-timing-switch-command-state = "dsi_lp_mode";
			qcom,mdss-dsi-timing-switch-command-update = <0x6c 0x03 0x01>;
			qcom,mdss-dsi-timing-switch-command = [39 00 00 40 00 00 03 f0 aa 1b 15 00 00 40 00 00 02 d0 00 15 00 00 40 00 00 02 75 00 15 00 00 40 00 00 02 6c 02 39 00 00 40 00 00 04 71 01 02 00 39 00 00 40 00 00 03 f0 aa 10 15 00 00 00 00 00 02 cf 16];
			qcom,mdss-dsi-on-command-state = "dsi_lp_mode";
			qcom,mdss-dsi-on-command = [39 00 00 40 00 00 03 f0 aa 10 15 00 00 40 00 00 02 65 01 15 00 00 40 00 00 02 d0 05 15 00 00 40 00 00 02 03 01 15 00 00 40 00 00 02 35 00 15 00 00 40 00 00 02 53 28 39 00 00 40 00 00 03 f0 aa 13 15 00 00 40 00 00 02 c8 10 15 00 00 40 00 00 02 d0 10 15 00 00 40 00 00 02 e0 10 15 00 00 40 00 00 02 e8 10 39 00 00 40 00 00 03 51 00 00 15 00 00 40 00 00 02 5e 00 15 00 00 40 00 00 02 59 09 39 00 00 40 00 00 03 ff 5a 81 15 00 00 40 00 00 02 65 1b 15 00 00 40 00 00 02 f8 04 15 00 00 40 00 00 02 65 1a 15 00 00 40 00 00 02 f8 0f 15 00 00 40 00 00 02 65 0a 15 00 00 00 00 00 02 f8 fb 39 00 00 40 00 00 03 f0 aa 1b 15 00 00 40 00 00 02 d0 00 15 00 00 00 00 00 02 75 00 15 00 00 40 00 00 02 6c 02 39 00 00 40 00 00 04 71 01 02 00 39 00 00 40 00 00 03 f0 aa 10 15 00 00 00 00 00 02 cf 16 15 00 00 40 00 00 02 6d 00 15 00 00 40 00 00 02 6f 02 15 00 00 40 00 00 02 72 00 39 00 00 00 00 00 60 70 12 00 00 ab 21 00 0a 6e 04 b0 00 1e 02 58 02 58 01 55 01 d2 00 0a 01 88 00 32 00 0d 03 97 11 48 08 00 0c 00 07 10 20 00 06 0f 0f 33 0e 1c 2a 38 46 54 62 69 70 77 79 7b 7d 7e 00 82 11 40 19 c0 22 3e 32 7c 3a ba 3a f8 3b 38 3b 38 3b 76 4b 76 4b 74 4b 74 5b b4 73 f4 01 00 00 00 00 00 00 39 00 00 40 00 00 03 f0 aa 10 39 00 00 40 00 00 0e bd 10 02 31 46 75 8a b9 01 32 45 76 89 ba 39 00 00 40 00 00 03 f0 aa 17 15 00 00 40 00 00 02 b0 11 39 00 00 40 00 00 07 c0 21 00 34 20 31 04 15 00 00 40 00 00 02 65 06 15 00 00 40 00 00 02 bf ff 39 00 00 40 00 00 03 ff 5a 80 15 00 00 40 00 00 02 65 0a 39 00 00 40 00 00 03 f9 9e 8f 15 00 00 40 00 00 02 65 0f 15 00 00 40 00 00 02 f9 14 39 00 00 40 00 00 03 ff 5a 81 15 00 00 40 00 00 02 65 03 15 00 00 40 00 00 02 f3 24 15 00 00 40 00 00 02 65 05 15 00 00 40 00 00 02 f3 a0 39 00 00 40 00 00 03 ff 5a 81 15 00 00 40 00 00 02 65 02 39 00 00 40 00 00 05 fb d3 d3 d3 d3 39 00 00 40 00 00 03 f0 aa 10 15 00 00 40 00 00 02 65 04 15 00 00 00 00 00 02 cf 4b 39 00 00 40 00 00 03 f0 aa 10 15 00 00 40 00 00 02 65 01 15 00 00 00 00 00 02 cf 07 39 00 00 40 00 00 03 f0 aa 10 15 00 00 40 00 00 02 65 03 15 00 00 00 00 00 02 cf 24 39 00 00 40 00 00 03 f0 aa 10 15 00 00 40 00 00 02 b6 00 39 00 00 40 00 00 03 ff 5a 82 15 00 00 40 00 00 02 65 04 15 00 00 00 00 00 02 f8 10 39 00 00 40 00 00 03 f0 aa 11 15 00 00 40 00 00 02 c0 00 15 00 00 40 00 00 02 65 09 39 00 00 40 00 00 04 c0 55 aa aa 39 00 00 40 00 00 0c c1 03 34 03 99 03 34 03 ff ff a6 00 15 00 00 40 00 00 02 55 01 39 00 00 40 00 00 03 f0 aa 10 15 00 00 40 00 00 02 65 07 15 00 00 40 00 00 02 d0 00 15 00 00 40 00 00 02 65 09 39 00 00 40 00 00 03 d0 03 19 15 00 00 40 00 00 02 65 0c 15 00 00 40 00 00 02 d0 00 15 00 00 40 00 00 02 65 0e 39 00 00 40 00 00 03 d0 03 19 15 00 00 40 00 00 02 65 11 15 00 00 40 00 00 02 d0 19 39 00 00 40 00 00 03 f0 aa 12 15 00 00 40 00 00 02 65 0b 15 00 00 40 00 00 02 d2 10 39 00 00 40 00 00 03 f0 aa 10 39 00 00 00 00 00 09 c4 34 34 34 34 34 34 34 34 39 00 00 40 00 00 03 f0 aa 12 15 00 00 40 00 00 02 d6 00 15 00 00 40 00 00 02 65 02 15 00 00 00 00 00 02 d1 00 39 00 00 40 00 00 03 5f 04 7e 39 00 00 40 00 00 03 f0 aa 12 39 00 00 40 00 00 20 c3 e1 20 30 01 cd 01 cd 01 cd 01 cd 01 cd 01 cd 01 cd 00 64 00 64 00 64 00 64 00 64 00 64 00 64 39 00 00 40 00 00 03 ff 5a 81 15 00 00 40 00 00 02 65 15 15 00 00 00 00 00 02 fc 7e 05 00 00 00 78 00 01 11 05 00 00 00 00 00 01 29];
			qcom,dsi-mode-te-width-us = <16888>;
			qcom,disable-rsc-solver;
			mi,mdss-dc-status-control-dc-6C-cfg = <0x02 0x00>;
			qcom,mdss-dsi-h-sync-skew = <0x00>;
			qcom,mdss-dsi-panel-framerate = <0x28>;
			cell-index = <0x02>;
			qcom,src-chroma-format = <0x01>;
			qcom,mdss-dsc-block-prediction-enable;
			qcom,mdss-dsc-bit-per-pixel = <0x08>;
			qcom,mdss-dsc-bit-per-component = <0x0a>;
			qcom,mdss-dsc-slice-per-pkt = <0x02>;
			qcom,mdss-dsc-slice-width = <0x258>;
			qcom,mdss-dsc-slice-height = <0x1e>;
			qcom,mdss-dsc-scr-version = <0x00>;
			qcom,mdss-dsc-version = <0x12>;
			qcom,compression-mode = "dsc";
			qcom,default-topology-index = <0x00>;
			qcom,display-topology = <0x02 0x02 0x01>;
			qcom,mdss-dsi-panel-phy-timings = [00 26 0a 0a 1b 19 0a 0a 0a 02 04 00 20 0f];
			qcom,mdss-mdp-transfer-time-us = <7300>;
			qcom,mdss-dsi-panel-jitter = <0x05 0x01>;
			qcom,mdss-dsi-panel-clockrate = <0x448b9b80>;
			qcom,mdss-dsi-v-bottom-border = <0x00>;
			qcom,mdss-dsi-v-top-border = <0x00>;
			qcom,mdss-dsi-h-right-border = <0x00>;
			qcom,mdss-dsi-h-left-border = <0x00>;
			qcom,mdss-dsi-h-sync-pulse = <0x00>;
			qcom,mdss-dsi-v-pulse-width = <0x08>;
			qcom,mdss-dsi-v-front-porch = <0x2d>;
			qcom,mdss-dsi-v-back-porch = <0x25>;
			qcom,mdss-dsi-h-pulse-width = <0x10>;
			qcom,mdss-dsi-h-back-porch = <0x20>;
			qcom,mdss-dsi-h-front-porch = <0x10>;
			qcom,mdss-dsi-panel-height = <0xa6e>;
			qcom,mdss-dsi-panel-width = <0x4b0>;
			mi,mdss-dsi-dimmingoff-command-state = "dsi_hs_mode";
			mi,mdss-dsi-dimmingoff-command = [15 00 00 00 00 00 02 53 20];
			mi,mdss-dsi-dimmingon-command-state = "dsi_hs_mode";
			mi,mdss-dsi-dimmingon-command = [15 00 00 00 00 00 02 53 28];
			mi,mdss-dsi-auto-current-limit-command-update = <0xc1 0x01 0x02>;
			mi,mdss-dsi-auto-current-limit-command-state = "dsi_lp_mode";
			mi,mdss-dsi-auto-current-limit-command = <0x39000040 0x3f0 0xaa113900 0x00 0x3c103ff>;
			mi,mdss-dsi-round-corner-off-command-state = "dsi_lp_mode";
			mi,mdss-dsi-round-corner-off-command = [39 00 00 40 00 00 03 f0 aa 18 15 00 00 00 00 00 02 b0 00];
			mi,mdss-dsi-round-corner-on-command-state = "dsi_lp_mode";
			mi,mdss-dsi-round-corner-on-command = [39 00 00 40 00 00 03 f0 aa 18 15 00 00 00 00 00 02 b0 80];
			mi,mdss-dsi-doze-lbm-nolp-command-state = "dsi_lp_mode";
			mi,mdss-dsi-doze-hbm-nolp-command-state = "dsi_lp_mode";
			mi,mdss-dsi-doze-lbm-nolp-command = [05 00 00 40 00 00 01 38 15 00 00 40 00 00 02 75 00 39 00 00 40 00 00 03 f0 aa 1b 15 00 00 40 00 00 02 d0 00 39 00 00 40 00 00 03 51 00 14 39 00 00 40 00 00 03 f0 aa 10 15 00 00 00 00 00 02 cf 16];
			mi,mdss-dsi-doze-hbm-nolp-command = [05 00 00 40 00 00 01 38 15 00 00 40 00 00 02 75 00 39 00 00 40 00 00 03 f0 aa 1b 15 00 00 40 00 00 02 d0 00 39 00 00 40 00 00 03 51 00 ee 39 00 00 40 00 00 03 f0 aa 10 15 00 00 00 00 00 02 cf 16];
			mi,mdss-dsi-doze-lbm-command-state = "dsi_lp_mode";
			mi,mdss-dsi-doze-lbm-command = [39 00 00 40 00 00 03 f0 aa 1b 15 00 00 40 00 00 02 d0 00 15 00 00 40 00 00 02 75 00 15 00 00 00 09 00 02 71 00 39 00 00 40 00 00 03 f0 aa 1b 39 00 00 40 00 00 0e d2 04 01 03 04 0b 0b 0b 0b 0b 00 0e e0 00 15 00 00 40 00 00 02 d0 11 05 00 00 40 00 00 01 39 15 00 00 40 00 00 02 6d 02 15 00 00 40 00 00 02 75 01 39 00 00 40 00 00 03 f0 aa 10 15 00 00 40 00 00 02 cf 09 15 00 00 40 00 00 02 53 20 39 00 00 00 00 00 03 51 00 12];
			mi,mdss-dsi-doze-hbm-command-state = "dsi_lp_mode";
			mi,mdss-dsi-doze-hbm-command = [39 00 00 40 00 00 03 f0 aa 1b 15 00 00 40 00 00 02 d0 00 15 00 00 40 00 00 02 75 00 15 00 00 00 09 00 02 71 00 39 00 00 40 00 00 03 f0 aa 1b 39 00 00 40 00 00 0e d2 04 01 03 04 0b 0b 0b 0b 0b 00 0e e0 00 15 00 00 40 00 00 02 d0 11 05 00 00 40 00 00 01 39 15 00 00 40 00 00 02 6d 00 15 00 00 40 00 00 02 75 01 39 00 00 40 00 00 03 f0 aa 10 15 00 00 40 00 00 02 cf 09 15 00 00 40 00 00 02 53 20 39 00 00 00 00 00 03 51 00 cf];
			mi,mdss-dsi-hbm-off-command-state = "dsi_hs_mode";
			mi,mdss-dsi-hbm-off-command = [39 00 00 40 00 00 03 f0 aa 10 15 00 00 40 00 00 02 65 01 15 00 00 40 00 00 02 d0 04 39 00 00 00 00 00 03 51 0a ab];
			mi,mdss-dsi-hbm-on-command-state = "dsi_hs_mode";
			mi,mdss-dsi-hbm-on-command = [39 00 00 40 00 00 03 f0 aa 10 15 00 00 40 00 00 02 65 01 15 00 00 40 00 00 02 d0 05 39 00 00 00 00 00 03 51 17 ff];
			mi,mdss-dsi-vint-off-command-state = "dsi_lp_mode";
			mi,mdss-dsi-vint-off-command = [39 00 00 40 00 00 03 f0 aa 12 39 00 00 40 00 00 02 bf 63 39 00 00 40 00 00 02 65 30 39 00 00 40 00 00 02 bf 63 39 00 00 40 00 00 02 d9 63 39 00 00 40 00 00 02 65 30 39 00 00 40 00 00 02 d9 63 39 00 00 40 00 00 02 df 63 39 00 00 40 00 00 02 65 30 39 00 00 40 00 00 02 df 63 39 00 00 40 00 00 02 eb 63 39 00 00 40 00 00 02 65 30 39 00 00 00 00 00 02 eb 63];
			qcom,mdss-dsi-off-command-state = "dsi_hs_mode";
			qcom,mdss-dsi-off-command = <0x5000000 0x128 0x5000000 0x78000110>;
		};

		timing@normal_30hz_index_03 {
			mi,mdss-dsi-dc-off-command-state = "dsi_lp_mode";
			mi,mdss-dsi-dc-off-command = [15 00 00 00 00 00 02 6c 00];
			mi,mdss-dsi-dc-on-command-state = "dsi_lp_mode";
			mi,mdss-dsi-dc-on-command = [15 00 00 00 00 00 02 6c 02];
			qcom,mdss-dsi-nolp-command-state = "dsi_lp_mode";
			qcom,mdss-dsi-nolp-command-update = <0x51 0x04 0x02 0x6c 0x07 0x01>;
			qcom,mdss-dsi-nolp-command = [05 00 00 40 00 00 01 38 15 00 00 40 00 00 02 75 00 39 00 00 40 00 00 03 f0 aa 1b 15 00 00 40 00 00 02 d0 00 39 00 00 40 00 00 03 51 00 00 39 00 00 40 00 00 03 f0 aa 10 15 00 00 00 09 00 02 cf 16 15 00 00 40 00 00 02 6c 02 39 00 00 40 00 00 04 71 01 03 00 39 00 00 00 00 00 03 f0 aa 00];
			qcom,mdss-dsi-timing-switch-command-state = "dsi_lp_mode";
			qcom,mdss-dsi-timing-switch-command-update = <0x6c 0x03 0x01>;
			qcom,mdss-dsi-timing-switch-command = [39 00 00 40 00 00 03 f0 aa 1b 15 00 00 40 00 00 02 d0 00 15 00 00 40 00 00 02 75 00 15 00 00 40 00 00 02 6c 02 39 00 00 40 00 00 04 71 01 03 00 39 00 00 40 00 00 03 f0 aa 10 15 00 00 00 00 00 02 cf 16];
			qcom,mdss-dsi-on-command-state = "dsi_lp_mode";
			qcom,mdss-dsi-on-command = [39 00 00 40 00 00 03 f0 aa 10 15 00 00 40 00 00 02 65 01 15 00 00 40 00 00 02 d0 05 15 00 00 40 00 00 02 03 01 15 00 00 40 00 00 02 35 00 15 00 00 40 00 00 02 53 28 39 00 00 40 00 00 03 f0 aa 13 15 00 00 40 00 00 02 c8 10 15 00 00 40 00 00 02 d0 10 15 00 00 40 00 00 02 e0 10 15 00 00 40 00 00 02 e8 10 39 00 00 40 00 00 03 51 00 00 15 00 00 40 00 00 02 5e 00 15 00 00 40 00 00 02 59 09 39 00 00 40 00 00 03 ff 5a 81 15 00 00 40 00 00 02 65 1b 15 00 00 40 00 00 02 f8 04 15 00 00 40 00 00 02 65 1a 15 00 00 40 00 00 02 f8 0f 15 00 00 40 00 00 02 65 0a 15 00 00 00 00 00 02 f8 fb 39 00 00 40 00 00 03 f0 aa 1b 15 00 00 40 00 00 02 d0 00 15 00 00 00 00 00 02 75 00 15 00 00 40 00 00 02 6c 02 39 00 00 40 00 00 04 71 01 03 00 39 00 00 40 00 00 03 f0 aa 10 15 00 00 00 00 00 02 cf 16 15 00 00 40 00 00 02 6d 00 15 00 00 40 00 00 02 6f 02 15 00 00 40 00 00 02 72 00 39 00 00 00 00 00 60 70 12 00 00 ab 21 00 0a 6e 04 b0 00 1e 02 58 02 58 01 55 01 d2 00 0a 01 88 00 32 00 0d 03 97 11 48 08 00 0c 00 07 10 20 00 06 0f 0f 33 0e 1c 2a 38 46 54 62 69 70 77 79 7b 7d 7e 00 82 11 40 19 c0 22 3e 32 7c 3a ba 3a f8 3b 38 3b 38 3b 76 4b 76 4b 74 4b 74 5b b4 73 f4 01 00 00 00 00 00 00 39 00 00 40 00 00 03 f0 aa 10 39 00 00 40 00 00 0e bd 10 02 31 46 75 8a b9 01 32 45 76 89 ba 39 00 00 40 00 00 03 f0 aa 17 15 00 00 40 00 00 02 b0 11 39 00 00 40 00 00 07 c0 21 00 34 20 31 04 15 00 00 40 00 00 02 65 06 15 00 00 40 00 00 02 bf ff 39 00 00 40 00 00 03 ff 5a 80 15 00 00 40 00 00 02 65 0a 39 00 00 40 00 00 03 f9 9e 8f 15 00 00 40 00 00 02 65 0f 15 00 00 40 00 00 02 f9 14 39 00 00 40 00 00 03 ff 5a 81 15 00 00 40 00 00 02 65 03 15 00 00 40 00 00 02 f3 24 15 00 00 40 00 00 02 65 05 15 00 00 40 00 00 02 f3 a0 39 00 00 40 00 00 03 ff 5a 81 15 00 00 40 00 00 02 65 02 39 00 00 40 00 00 05 fb d3 d3 d3 d3 39 00 00 40 00 00 03 f0 aa 10 15 00 00 40 00 00 02 65 04 15 00 00 00 00 00 02 cf 4b 39 00 00 40 00 00 03 f0 aa 10 15 00 00 40 00 00 02 65 01 15 00 00 00 00 00 02 cf 07 39 00 00 40 00 00 03 f0 aa 10 15 00 00 40 00 00 02 65 03 15 00 00 00 00 00 02 cf 24 39 00 00 40 00 00 03 f0 aa 10 15 00 00 40 00 00 02 b6 00 39 00 00 40 00 00 03 ff 5a 82 15 00 00 40 00 00 02 65 04 15 00 00 00 00 00 02 f8 10 39 00 00 40 00 00 03 f0 aa 11 15 00 00 40 00 00 02 c0 00 15 00 00 40 00 00 02 65 09 39 00 00 40 00 00 04 c0 55 aa aa 39 00 00 40 00 00 0c c1 03 34 03 99 03 34 03 ff ff a6 00 15 00 00 40 00 00 02 55 01 39 00 00 40 00 00 03 f0 aa 10 15 00 00 40 00 00 02 65 07 15 00 00 40 00 00 02 d0 00 15 00 00 40 00 00 02 65 09 39 00 00 40 00 00 03 d0 03 19 15 00 00 40 00 00 02 65 0c 15 00 00 40 00 00 02 d0 00 15 00 00 40 00 00 02 65 0e 39 00 00 40 00 00 03 d0 03 19 15 00 00 40 00 00 02 65 11 15 00 00 40 00 00 02 d0 19 39 00 00 40 00 00 03 f0 aa 12 15 00 00 40 00 00 02 65 0b 15 00 00 40 00 00 02 d2 10 39 00 00 40 00 00 03 f0 aa 10 39 00 00 00 00 00 09 c4 34 34 34 34 34 34 34 34 39 00 00 40 00 00 03 f0 aa 12 15 00 00 40 00 00 02 d6 00 15 00 00 40 00 00 02 65 02 15 00 00 00 00 00 02 d1 00 39 00 00 40 00 00 03 5f 04 7e 39 00 00 40 00 00 03 f0 aa 12 39 00 00 40 00 00 20 c3 e1 20 30 01 cd 01 cd 01 cd 01 cd 01 cd 01 cd 01 cd 00 64 00 64 00 64 00 64 00 64 00 64 00 64 39 00 00 40 00 00 03 ff 5a 81 15 00 00 40 00 00 02 65 15 15 00 00 00 00 00 02 fc 7e 05 00 00 00 78 00 01 11 05 00 00 00 00 00 01 29];
			qcom,dsi-mode-te-width-us = <25210>;
			qcom,disable-rsc-solver;
			mi,mdss-dc-status-control-dc-6C-cfg = <0x02 0x00>;
			qcom,mdss-dsi-h-sync-skew = <0x00>;
			qcom,mdss-dsi-panel-framerate = <0x1e>;
			cell-index = <0x03>;
			qcom,src-chroma-format = <0x01>;
			qcom,mdss-dsc-block-prediction-enable;
			qcom,mdss-dsc-bit-per-pixel = <0x08>;
			qcom,mdss-dsc-bit-per-component = <0x0a>;
			qcom,mdss-dsc-slice-per-pkt = <0x02>;
			qcom,mdss-dsc-slice-width = <0x258>;
			qcom,mdss-dsc-slice-height = <0x1e>;
			qcom,mdss-dsc-scr-version = <0x00>;
			qcom,mdss-dsc-version = <0x12>;
			qcom,compression-mode = "dsc";
			qcom,default-topology-index = <0x00>;
			qcom,display-topology = <0x02 0x02 0x01>;
			qcom,mdss-dsi-panel-phy-timings = [00 26 0a 0a 1b 19 0a 0a 0a 02 04 00 20 0f];
			qcom,mdss-mdp-transfer-time-us = <7300>;
			qcom,mdss-dsi-panel-jitter = <0x05 0x01>;
			qcom,mdss-dsi-panel-clockrate = <0x448b9b80>;
			qcom,mdss-dsi-v-bottom-border = <0x00>;
			qcom,mdss-dsi-v-top-border = <0x00>;
			qcom,mdss-dsi-h-right-border = <0x00>;
			qcom,mdss-dsi-h-left-border = <0x00>;
			qcom,mdss-dsi-h-sync-pulse = <0x00>;
			qcom,mdss-dsi-v-pulse-width = <0x08>;
			qcom,mdss-dsi-v-front-porch = <0x2d>;
			qcom,mdss-dsi-v-back-porch = <0x25>;
			qcom,mdss-dsi-h-pulse-width = <0x10>;
			qcom,mdss-dsi-h-back-porch = <0x20>;
			qcom,mdss-dsi-h-front-porch = <0x10>;
			qcom,mdss-dsi-panel-height = <0xa6e>;
			qcom,mdss-dsi-panel-width = <0x4b0>;
			mi,mdss-dsi-dimmingoff-command-state = "dsi_hs_mode";
			mi,mdss-dsi-dimmingoff-command = [15 00 00 00 00 00 02 53 20];
			mi,mdss-dsi-dimmingon-command-state = "dsi_hs_mode";
			mi,mdss-dsi-dimmingon-command = [15 00 00 00 00 00 02 53 28];
			mi,mdss-dsi-auto-current-limit-command-update = <0xc1 0x01 0x02>;
			mi,mdss-dsi-auto-current-limit-command-state = "dsi_lp_mode";
			mi,mdss-dsi-auto-current-limit-command = <0x39000040 0x3f0 0xaa113900 0x00 0x3c103ff>;
			mi,mdss-dsi-round-corner-off-command-state = "dsi_lp_mode";
			mi,mdss-dsi-round-corner-off-command = [39 00 00 40 00 00 03 f0 aa 18 15 00 00 00 00 00 02 b0 00];
			mi,mdss-dsi-round-corner-on-command-state = "dsi_lp_mode";
			mi,mdss-dsi-round-corner-on-command = [39 00 00 40 00 00 03 f0 aa 18 15 00 00 00 00 00 02 b0 80];
			mi,mdss-dsi-doze-lbm-nolp-command-state = "dsi_lp_mode";
			mi,mdss-dsi-doze-hbm-nolp-command-state = "dsi_lp_mode";
			mi,mdss-dsi-doze-lbm-nolp-command = [05 00 00 40 00 00 01 38 15 00 00 40 00 00 02 75 00 39 00 00 40 00 00 03 f0 aa 1b 15 00 00 40 00 00 02 d0 00 39 00 00 40 00 00 03 51 00 14 39 00 00 40 00 00 03 f0 aa 10 15 00 00 00 00 00 02 cf 16];
			mi,mdss-dsi-doze-hbm-nolp-command = [05 00 00 40 00 00 01 38 15 00 00 40 00 00 02 75 00 39 00 00 40 00 00 03 f0 aa 1b 15 00 00 40 00 00 02 d0 00 39 00 00 40 00 00 03 51 00 ee 39 00 00 40 00 00 03 f0 aa 10 15 00 00 00 00 00 02 cf 16];
			mi,mdss-dsi-doze-lbm-command-state = "dsi_lp_mode";
			mi,mdss-dsi-doze-lbm-command = [39 00 00 40 00 00 03 f0 aa 1b 15 00 00 40 00 00 02 d0 00 15 00 00 40 00 00 02 75 00 15 00 00 00 09 00 02 71 00 39 00 00 40 00 00 03 f0 aa 1b 39 00 00 40 00 00 0e d2 04 01 03 04 0b 0b 0b 0b 0b 00 0e e0 00 15 00 00 40 00 00 02 d0 11 05 00 00 40 00 00 01 39 15 00 00 40 00 00 02 6d 02 15 00 00 40 00 00 02 75 01 39 00 00 40 00 00 03 f0 aa 10 15 00 00 40 00 00 02 cf 09 15 00 00 40 00 00 02 53 20 39 00 00 00 00 00 03 51 00 12];
			mi,mdss-dsi-doze-hbm-command-state = "dsi_lp_mode";
			mi,mdss-dsi-doze-hbm-command = [39 00 00 40 00 00 03 f0 aa 1b 15 00 00 40 00 00 02 d0 00 15 00 00 40 00 00 02 75 00 15 00 00 00 09 00 02 71 00 39 00 00 40 00 00 03 f0 aa 1b 39 00 00 40 00 00 0e d2 04 01 03 04 0b 0b 0b 0b 0b 00 0e e0 00 15 00 00 40 00 00 02 d0 11 05 00 00 40 00 00 01 39 15 00 00 40 00 00 02 6d 00 15 00 00 40 00 00 02 75 01 39 00 00 40 00 00 03 f0 aa 10 15 00 00 40 00 00 02 cf 09 15 00 00 40 00 00 02 53 20 39 00 00 00 00 00 03 51 00 cf];
			mi,mdss-dsi-hbm-off-command-state = "dsi_hs_mode";
			mi,mdss-dsi-hbm-off-command = [39 00 00 40 00 00 03 f0 aa 10 15 00 00 40 00 00 02 65 01 15 00 00 40 00 00 02 d0 04 39 00 00 00 00 00 03 51 0a ab];
			mi,mdss-dsi-hbm-on-command-state = "dsi_hs_mode";
			mi,mdss-dsi-hbm-on-command = [39 00 00 40 00 00 03 f0 aa 10 15 00 00 40 00 00 02 65 01 15 00 00 40 00 00 02 d0 05 39 00 00 00 00 00 03 51 17 ff];
			mi,mdss-dsi-vint-off-command-state = "dsi_lp_mode";
			mi,mdss-dsi-vint-off-command = [39 00 00 40 00 00 03 f0 aa 12 39 00 00 40 00 00 02 bf 63 39 00 00 40 00 00 02 65 30 39 00 00 40 00 00 02 bf 63 39 00 00 40 00 00 02 d9 63 39 00 00 40 00 00 02 65 30 39 00 00 40 00 00 02 d9 63 39 00 00 40 00 00 02 df 63 39 00 00 40 00 00 02 65 30 39 00 00 40 00 00 02 df 63 39 00 00 40 00 00 02 eb 63 39 00 00 40 00 00 02 65 30 39 00 00 00 00 00 02 eb 63];
			qcom,mdss-dsi-off-command-state = "dsi_hs_mode";
			qcom,mdss-dsi-off-command = <0x5000000 0x128 0x5000000 0x78000110>;
		};

		timing@normal_24hz_index_04 {
			mi,mdss-dsi-dc-off-command-state = "dsi_lp_mode";
			mi,mdss-dsi-dc-off-command = [15 00 00 00 00 00 02 6c 00];
			mi,mdss-dsi-dc-on-command-state = "dsi_lp_mode";
			mi,mdss-dsi-dc-on-command = [15 00 00 00 00 00 02 6c 02];
			qcom,mdss-dsi-nolp-command-state = "dsi_lp_mode";
			qcom,mdss-dsi-nolp-command-update = <0x51 0x04 0x02 0x6c 0x07 0x01>;
			qcom,mdss-dsi-nolp-command = [05 00 00 40 00 00 01 38 15 00 00 40 00 00 02 75 00 39 00 00 40 00 00 03 f0 aa 1b 15 00 00 40 00 00 02 d0 00 39 00 00 40 00 00 03 51 00 00 39 00 00 40 00 00 03 f0 aa 10 15 00 00 00 09 00 02 cf 16 15 00 00 40 00 00 02 6c 02 39 00 00 40 00 00 04 71 01 04 00 39 00 00 00 00 00 03 f0 aa 00];
			qcom,mdss-dsi-timing-switch-command-state = "dsi_lp_mode";
			qcom,mdss-dsi-timing-switch-command-update = <0x6c 0x03 0x01>;
			qcom,mdss-dsi-timing-switch-command = [39 00 00 40 00 00 03 f0 aa 1b 15 00 00 40 00 00 02 d0 00 15 00 00 40 00 00 02 75 00 15 00 00 40 00 00 02 6c 02 39 00 00 40 00 00 04 71 01 04 00 39 00 00 40 00 00 03 f0 aa 10 15 00 00 00 00 00 02 cf 16];
			qcom,mdss-dsi-on-command-state = "dsi_lp_mode";
			qcom,mdss-dsi-on-command = [39 00 00 40 00 00 03 f0 aa 10 15 00 00 40 00 00 02 65 01 15 00 00 40 00 00 02 d0 05 15 00 00 40 00 00 02 03 01 15 00 00 40 00 00 02 35 00 15 00 00 40 00 00 02 53 28 39 00 00 40 00 00 03 f0 aa 13 15 00 00 40 00 00 02 c8 10 15 00 00 40 00 00 02 d0 10 15 00 00 40 00 00 02 e0 10 15 00 00 40 00 00 02 e8 10 39 00 00 40 00 00 03 51 00 00 15 00 00 40 00 00 02 5e 00 15 00 00 40 00 00 02 59 09 39 00 00 40 00 00 03 ff 5a 81 15 00 00 40 00 00 02 65 1b 15 00 00 40 00 00 02 f8 04 15 00 00 40 00 00 02 65 1a 15 00 00 40 00 00 02 f8 0f 15 00 00 40 00 00 02 65 0a 15 00 00 00 00 00 02 f8 fb 39 00 00 40 00 00 03 f0 aa 1b 15 00 00 40 00 00 02 d0 00 15 00 00 00 00 00 02 75 00 15 00 00 40 00 00 02 6c 02 39 00 00 40 00 00 04 71 01 04 00 39 00 00 40 00 00 03 f0 aa 10 15 00 00 00 00 00 02 cf 16 15 00 00 40 00 00 02 6d 00 15 00 00 40 00 00 02 6f 02 15 00 00 40 00 00 02 72 00 39 00 00 00 00 00 60 70 12 00 00 ab 21 00 0a 6e 04 b0 00 1e 02 58 02 58 01 55 01 d2 00 0a 01 88 00 32 00 0d 03 97 11 48 08 00 0c 00 07 10 20 00 06 0f 0f 33 0e 1c 2a 38 46 54 62 69 70 77 79 7b 7d 7e 00 82 11 40 19 c0 22 3e 32 7c 3a ba 3a f8 3b 38 3b 38 3b 76 4b 76 4b 74 4b 74 5b b4 73 f4 01 00 00 00 00 00 00 39 00 00 40 00 00 03 f0 aa 10 39 00 00 40 00 00 0e bd 10 02 31 46 75 8a b9 01 32 45 76 89 ba 39 00 00 40 00 00 03 f0 aa 17 15 00 00 40 00 00 02 b0 11 39 00 00 40 00 00 07 c0 21 00 34 20 31 04 15 00 00 40 00 00 02 65 06 15 00 00 40 00 00 02 bf ff 39 00 00 40 00 00 03 ff 5a 80 15 00 00 40 00 00 02 65 0a 39 00 00 40 00 00 03 f9 9e 8f 15 00 00 40 00 00 02 65 0f 15 00 00 40 00 00 02 f9 14 39 00 00 40 00 00 03 ff 5a 81 15 00 00 40 00 00 02 65 03 15 00 00 40 00 00 02 f3 24 15 00 00 40 00 00 02 65 05 15 00 00 40 00 00 02 f3 a0 39 00 00 40 00 00 03 ff 5a 81 15 00 00 40 00 00 02 65 02 39 00 00 40 00 00 05 fb d3 d3 d3 d3 39 00 00 40 00 00 03 f0 aa 10 15 00 00 40 00 00 02 65 04 15 00 00 00 00 00 02 cf 4b 39 00 00 40 00 00 03 f0 aa 10 15 00 00 40 00 00 02 65 01 15 00 00 00 00 00 02 cf 07 39 00 00 40 00 00 03 f0 aa 10 15 00 00 40 00 00 02 65 03 15 00 00 00 00 00 02 cf 24 39 00 00 40 00 00 03 f0 aa 10 15 00 00 40 00 00 02 b6 00 39 00 00 40 00 00 03 ff 5a 82 15 00 00 40 00 00 02 65 04 15 00 00 00 00 00 02 f8 10 39 00 00 40 00 00 03 f0 aa 11 15 00 00 40 00 00 02 c0 00 15 00 00 40 00 00 02 65 09 39 00 00 40 00 00 04 c0 55 aa aa 39 00 00 40 00 00 0c c1 03 34 03 99 03 34 03 ff ff a6 00 15 00 00 40 00 00 02 55 01 39 00 00 40 00 00 03 f0 aa 10 15 00 00 40 00 00 02 65 07 15 00 00 40 00 00 02 d0 00 15 00 00 40 00 00 02 65 09 39 00 00 40 00 00 03 d0 03 19 15 00 00 40 00 00 02 65 0c 15 00 00 40 00 00 02 d0 00 15 00 00 40 00 00 02 65 0e 39 00 00 40 00 00 03 d0 03 19 15 00 00 40 00 00 02 65 11 15 00 00 40 00 00 02 d0 19 39 00 00 40 00 00 03 f0 aa 12 15 00 00 40 00 00 02 65 0b 15 00 00 40 00 00 02 d2 10 39 00 00 40 00 00 03 f0 aa 10 39 00 00 00 00 00 09 c4 34 34 34 34 34 34 34 34 39 00 00 40 00 00 03 f0 aa 12 15 00 00 40 00 00 02 d6 00 15 00 00 40 00 00 02 65 02 15 00 00 00 00 00 02 d1 00 39 00 00 40 00 00 03 5f 04 7e 39 00 00 40 00 00 03 f0 aa 12 39 00 00 40 00 00 20 c3 e1 20 30 01 cd 01 cd 01 cd 01 cd 01 cd 01 cd 01 cd 00 64 00 64 00 64 00 64 00 64 00 64 00 64 39 00 00 40 00 00 03 ff 5a 81 15 00 00 40 00 00 02 65 15 15 00 00 00 00 00 02 fc 7e 05 00 00 00 78 00 01 11 05 00 00 00 00 00 01 29];
			qcom,dsi-mode-te-width-us = <33531>;
			qcom,disable-rsc-solver;
			mi,mdss-dc-status-control-dc-6C-cfg = <0x02 0x00>;
			qcom,mdss-dsi-h-sync-skew = <0x00>;
			qcom,mdss-dsi-panel-framerate = <0x18>;
			cell-index = <0x04>;
			qcom,src-chroma-format = <0x01>;
			qcom,mdss-dsc-block-prediction-enable;
			qcom,mdss-dsc-bit-per-pixel = <0x08>;
			qcom,mdss-dsc-bit-per-component = <0x0a>;
			qcom,mdss-dsc-slice-per-pkt = <0x02>;
			qcom,mdss-dsc-slice-width = <0x258>;
			qcom,mdss-dsc-slice-height = <0x1e>;
			qcom,mdss-dsc-scr-version = <0x00>;
			qcom,mdss-dsc-version = <0x12>;
			qcom,compression-mode = "dsc";
			qcom,default-topology-index = <0x00>;
			qcom,display-topology = <0x02 0x02 0x01>;
			qcom,mdss-dsi-panel-phy-timings = [00 26 0a 0a 1b 19 0a 0a 0a 02 04 00 20 0f];
			qcom,mdss-mdp-transfer-time-us = <7300>;
			qcom,mdss-dsi-panel-jitter = <0x05 0x01>;
			qcom,mdss-dsi-panel-clockrate = <0x448b9b80>;
			qcom,mdss-dsi-v-bottom-border = <0x00>;
			qcom,mdss-dsi-v-top-border = <0x00>;
			qcom,mdss-dsi-h-right-border = <0x00>;
			qcom,mdss-dsi-h-left-border = <0x00>;
			qcom,mdss-dsi-h-sync-pulse = <0x00>;
			qcom,mdss-dsi-v-pulse-width = <0x08>;
			qcom,mdss-dsi-v-front-porch = <0x2d>;
			qcom,mdss-dsi-v-back-porch = <0x25>;
			qcom,mdss-dsi-h-pulse-width = <0x10>;
			qcom,mdss-dsi-h-back-porch = <0x20>;
			qcom,mdss-dsi-h-front-porch = <0x10>;
			qcom,mdss-dsi-panel-height = <0xa6e>;
			qcom,mdss-dsi-panel-width = <0x4b0>;
			mi,mdss-dsi-dimmingoff-command-state = "dsi_hs_mode";
			mi,mdss-dsi-dimmingoff-command = [15 00 00 00 00 00 02 53 20];
			mi,mdss-dsi-dimmingon-command-state = "dsi_hs_mode";
			mi,mdss-dsi-dimmingon-command = [15 00 00 00 00 00 02 53 28];
			mi,mdss-dsi-auto-current-limit-command-update = <0xc1 0x01 0x02>;
			mi,mdss-dsi-auto-current-limit-command-state = "dsi_lp_mode";
			mi,mdss-dsi-auto-current-limit-command = <0x39000040 0x3f0 0xaa113900 0x00 0x3c103ff>;
			mi,mdss-dsi-round-corner-off-command-state = "dsi_lp_mode";
			mi,mdss-dsi-round-corner-off-command = [39 00 00 40 00 00 03 f0 aa 18 15 00 00 00 00 00 02 b0 00];
			mi,mdss-dsi-round-corner-on-command-state = "dsi_lp_mode";
			mi,mdss-dsi-round-corner-on-command = [39 00 00 40 00 00 03 f0 aa 18 15 00 00 00 00 00 02 b0 80];
			mi,mdss-dsi-doze-lbm-nolp-command-state = "dsi_lp_mode";
			mi,mdss-dsi-doze-hbm-nolp-command-state = "dsi_lp_mode";
			mi,mdss-dsi-doze-lbm-nolp-command = [05 00 00 40 00 00 01 38 15 00 00 40 00 00 02 75 00 39 00 00 40 00 00 03 f0 aa 1b 15 00 00 40 00 00 02 d0 00 39 00 00 40 00 00 03 51 00 14 39 00 00 40 00 00 03 f0 aa 10 15 00 00 00 00 00 02 cf 16];
			mi,mdss-dsi-doze-hbm-nolp-command = [05 00 00 40 00 00 01 38 15 00 00 40 00 00 02 75 00 39 00 00 40 00 00 03 f0 aa 1b 15 00 00 40 00 00 02 d0 00 39 00 00 40 00 00 03 51 00 ee 39 00 00 40 00 00 03 f0 aa 10 15 00 00 00 00 00 02 cf 16];
			mi,mdss-dsi-doze-lbm-command-state = "dsi_lp_mode";
			mi,mdss-dsi-doze-lbm-command = [39 00 00 40 00 00 03 f0 aa 1b 15 00 00 40 00 00 02 d0 00 15 00 00 40 00 00 02 75 00 15 00 00 00 09 00 02 71 00 39 00 00 40 00 00 03 f0 aa 1b 39 00 00 40 00 00 0e d2 04 01 03 04 0b 0b 0b 0b 0b 00 0e e0 00 15 00 00 40 00 00 02 d0 11 05 00 00 40 00 00 01 39 15 00 00 40 00 00 02 6d 02 15 00 00 40 00 00 02 75 01 39 00 00 40 00 00 03 f0 aa 10 15 00 00 40 00 00 02 cf 09 15 00 00 40 00 00 02 53 20 39 00 00 00 00 00 03 51 00 12];
			mi,mdss-dsi-doze-hbm-command-state = "dsi_lp_mode";
			mi,mdss-dsi-doze-hbm-command = [39 00 00 40 00 00 03 f0 aa 1b 15 00 00 40 00 00 02 d0 00 15 00 00 40 00 00 02 75 00 15 00 00 00 09 00 02 71 00 39 00 00 40 00 00 03 f0 aa 1b 39 00 00 40 00 00 0e d2 04 01 03 04 0b 0b 0b 0b 0b 00 0e e0 00 15 00 00 40 00 00 02 d0 11 05 00 00 40 00 00 01 39 15 00 00 40 00 00 02 6d 00 15 00 00 40 00 00 02 75 01 39 00 00 40 00 00 03 f0 aa 10 15 00 00 40 00 00 02 cf 09 15 00 00 40 00 00 02 53 20 39 00 00 00 00 00 03 51 00 cf];
			mi,mdss-dsi-hbm-off-command-state = "dsi_hs_mode";
			mi,mdss-dsi-hbm-off-command = [39 00 00 40 00 00 03 f0 aa 10 15 00 00 40 00 00 02 65 01 15 00 00 40 00 00 02 d0 04 39 00 00 00 00 00 03 51 0a ab];
			mi,mdss-dsi-hbm-on-command-state = "dsi_hs_mode";
			mi,mdss-dsi-hbm-on-command = [39 00 00 40 00 00 03 f0 aa 10 15 00 00 40 00 00 02 65 01 15 00 00 40 00 00 02 d0 05 39 00 00 00 00 00 03 51 17 ff];
			mi,mdss-dsi-vint-off-command-state = "dsi_lp_mode";
			mi,mdss-dsi-vint-off-command = [39 00 00 40 00 00 03 f0 aa 12 39 00 00 40 00 00 02 bf 63 39 00 00 40 00 00 02 65 30 39 00 00 40 00 00 02 bf 63 39 00 00 40 00 00 02 d9 63 39 00 00 40 00 00 02 65 30 39 00 00 40 00 00 02 d9 63 39 00 00 40 00 00 02 df 63 39 00 00 40 00 00 02 65 30 39 00 00 40 00 00 02 df 63 39 00 00 40 00 00 02 eb 63 39 00 00 40 00 00 02 65 30 39 00 00 00 00 00 02 eb 63];
			qcom,mdss-dsi-off-command-state = "dsi_hs_mode";
			qcom,mdss-dsi-off-command = <0x5000000 0x128 0x5000000 0x78000110>;
		};

		timing@auto_120_to_1hz_index_05 {
			mi,mdss-dsi-dc-off-command-state = "dsi_lp_mode";
			mi,mdss-dsi-dc-off-command = [15 00 00 00 00 00 02 6c 00];
			mi,mdss-dsi-dc-on-command-state = "dsi_lp_mode";
			mi,mdss-dsi-dc-on-command = [15 00 00 00 00 00 02 6c 02];
			qcom,mdss-dsi-nolp-command-state = "dsi_lp_mode";
			qcom,mdss-dsi-nolp-command-update = <0x51 0x0b 0x02 0x6c 0x01 0x01>;
			qcom,mdss-dsi-nolp-command = <0x5000040 0x138 0x15000040 0x26c 0x2150000 0x40000002 0x71001500 0x400000 0x2750139 0x4000 0x3f0aa 0x1b150000 0x40000002 0x650c3900 0x400000 0x5d57777 0x77771500 0x400000 0x2650c39 0x4000 0x5d777 0x77777739 0x4000 0xed204 0x103040b 0xb0b0b0b 0xee000 0x15000040 0x2d0 0x11390000 0x40000003 0x51000039 0x4000 0x3f0aa 0x10150000 0x90002 0xcf093900 0x00 0x3f0aa00>;
			qcom,mdss-dsi-timing-switch-command-state = "dsi_lp_mode";
			qcom,mdss-dsi-timing-switch-command = [15 00 00 40 00 00 02 71 00 15 00 00 40 00 00 02 75 01 39 00 00 40 00 00 03 f0 aa 1b 15 00 00 40 00 00 02 65 0c 39 00 00 40 00 00 05 d5 77 77 77 77 15 00 00 40 00 00 02 65 0c 39 00 00 40 00 00 05 d7 77 77 77 77 39 00 00 40 00 00 0e d2 04 01 03 04 0b 0b 0b 0b 0b 00 0e e0 00 15 00 00 40 00 00 02 d0 11 39 00 00 40 00 00 03 f0 aa 10 15 00 00 00 00 00 02 cf 09];
			mi,mdss-dsi-timing-switch-from-normal-mode-command-state = "dsi_lp_mode";
			mi,mdss-dsi-timing-switch-from-normal-mode-command-update = <0x6c 0x00 0x01>;
			mi,mdss-dsi-timing-switch-from-normal-mode-command = [15 00 00 00 00 00 02 6c 00];
			mi,mdss-dsi-timing-switch-from-skip-mode-command-state = "dsi_lp_mode";
			mi,mdss-dsi-timing-switch-from-skip-mode-command-update = <0x6c 0x01 0x01>;
			mi,mdss-dsi-timing-switch-from-skip-mode-command = [15 00 00 40 00 00 02 71 00 15 00 00 00 0a 00 02 6c 00];
			mi,mdss-dsi-timing-switch-from-auto-mode-command-state = "dsi_lp_mode";
			mi,mdss-dsi-timing-switch-from-auto-mode-command-update = <0x6c 0x01 0x01>;
			mi,mdss-dsi-timing-switch-from-auto-mode-command = [15 00 00 40 00 00 02 71 00 15 00 00 40 00 00 02 6c 02 39 00 00 40 00 00 03 f0 aa 1b 15 00 00 40 00 00 02 d0 00 15 00 00 00 0a 00 02 75 00];
			qcom,mdss-dsi-on-command-state = "dsi_lp_mode";
			qcom,mdss-dsi-on-command = [39 00 00 40 00 00 03 f0 aa 10 15 00 00 40 00 00 02 65 01 15 00 00 40 00 00 02 d0 05 15 00 00 40 00 00 02 03 01 15 00 00 40 00 00 02 35 00 15 00 00 40 00 00 02 53 28 39 00 00 40 00 00 03 f0 aa 13 15 00 00 40 00 00 02 c8 10 15 00 00 40 00 00 02 d0 10 15 00 00 40 00 00 02 e0 10 15 00 00 40 00 00 02 e8 10 39 00 00 40 00 00 03 51 00 00 15 00 00 40 00 00 02 5e 00 15 00 00 40 00 00 02 59 09 39 00 00 40 00 00 03 ff 5a 81 15 00 00 40 00 00 02 65 1b 15 00 00 40 00 00 02 f8 04 15 00 00 40 00 00 02 65 1a 15 00 00 40 00 00 02 f8 0f 15 00 00 40 00 00 02 65 0a 15 00 00 00 00 00 02 f8 fb 15 00 00 40 00 00 02 6c 02 15 00 00 40 00 00 02 71 00 15 00 00 40 00 00 02 75 01 39 00 00 40 00 00 03 f0 aa 1b 15 00 00 40 00 00 02 65 0c 39 00 00 40 00 00 05 d5 77 77 77 77 15 00 00 40 00 00 02 65 0c 39 00 00 40 00 00 05 d7 77 77 77 77 39 00 00 40 00 00 0e d2 04 01 03 04 0b 0b 0b 0b 0b 00 0e e0 00 15 00 00 40 00 00 02 d0 11 39 00 00 40 00 00 03 f0 aa 10 15 00 00 00 00 00 02 cf 09 15 00 00 40 00 00 02 6d 00 15 00 00 40 00 00 02 6f 02 15 00 00 40 00 00 02 72 00 39 00 00 00 00 00 60 70 12 00 00 ab 21 00 0a 6e 04 b0 00 1e 02 58 02 58 01 55 01 d2 00 0a 01 88 00 32 00 0d 03 97 11 48 08 00 0c 00 07 10 20 00 06 0f 0f 33 0e 1c 2a 38 46 54 62 69 70 77 79 7b 7d 7e 00 82 11 40 19 c0 22 3e 32 7c 3a ba 3a f8 3b 38 3b 38 3b 76 4b 76 4b 74 4b 74 5b b4 73 f4 01 00 00 00 00 00 00 39 00 00 40 00 00 03 f0 aa 10 39 00 00 40 00 00 0e bd 10 02 31 46 75 8a b9 01 32 45 76 89 ba 39 00 00 40 00 00 03 f0 aa 17 15 00 00 40 00 00 02 b0 11 39 00 00 40 00 00 07 c0 21 00 34 20 31 04 15 00 00 40 00 00 02 65 06 15 00 00 40 00 00 02 bf ff 39 00 00 40 00 00 03 ff 5a 80 15 00 00 40 00 00 02 65 0a 39 00 00 40 00 00 03 f9 9e 8f 15 00 00 40 00 00 02 65 0f 15 00 00 40 00 00 02 f9 14 39 00 00 40 00 00 03 ff 5a 81 15 00 00 40 00 00 02 65 03 15 00 00 40 00 00 02 f3 24 15 00 00 40 00 00 02 65 05 15 00 00 40 00 00 02 f3 a0 39 00 00 40 00 00 03 ff 5a 81 15 00 00 40 00 00 02 65 02 39 00 00 40 00 00 05 fb d3 d3 d3 d3 39 00 00 40 00 00 03 f0 aa 10 15 00 00 40 00 00 02 65 04 15 00 00 00 00 00 02 cf 4b 39 00 00 40 00 00 03 f0 aa 10 15 00 00 40 00 00 02 65 01 15 00 00 00 00 00 02 cf 07 39 00 00 40 00 00 03 f0 aa 10 15 00 00 40 00 00 02 65 03 15 00 00 00 00 00 02 cf 24 39 00 00 40 00 00 03 f0 aa 10 15 00 00 40 00 00 02 b6 00 39 00 00 40 00 00 03 ff 5a 82 15 00 00 40 00 00 02 65 04 15 00 00 00 00 00 02 f8 10 39 00 00 40 00 00 03 f0 aa 11 15 00 00 40 00 00 02 c0 00 15 00 00 40 00 00 02 65 09 39 00 00 40 00 00 04 c0 55 aa aa 39 00 00 40 00 00 0c c1 03 34 03 99 03 34 03 ff ff a6 00 15 00 00 40 00 00 02 55 01 39 00 00 40 00 00 03 f0 aa 10 15 00 00 40 00 00 02 65 07 15 00 00 40 00 00 02 d0 00 15 00 00 40 00 00 02 65 09 39 00 00 40 00 00 03 d0 03 19 15 00 00 40 00 00 02 65 0c 15 00 00 40 00 00 02 d0 00 15 00 00 40 00 00 02 65 0e 39 00 00 40 00 00 03 d0 03 19 15 00 00 40 00 00 02 65 11 15 00 00 40 00 00 02 d0 19 39 00 00 40 00 00 03 f0 aa 12 15 00 00 40 00 00 02 65 0b 15 00 00 40 00 00 02 d2 10 39 00 00 40 00 00 03 f0 aa 10 39 00 00 00 00 00 09 c4 34 34 34 34 34 34 34 34 39 00 00 40 00 00 03 f0 aa 12 15 00 00 40 00 00 02 d6 00 15 00 00 40 00 00 02 65 02 15 00 00 00 00 00 02 d1 00 39 00 00 40 00 00 03 5f 04 7e 39 00 00 40 00 00 03 f0 aa 12 39 00 00 40 00 00 20 c3 e1 20 30 01 cd 01 cd 01 cd 01 cd 01 cd 01 cd 01 cd 00 64 00 64 00 64 00 64 00 64 00 64 00 64 39 00 00 40 00 00 03 ff 5a 81 15 00 00 40 00 00 02 65 15 15 00 00 00 00 00 02 fc 7e 05 00 00 00 78 00 01 11 05 00 00 00 00 00 01 29];
			qcom,dsi-mode-te-width-us = <245>;
			mi,mdss-dsi-ddic-min-framerate = <0x01>;
			mi,mdss-dsi-sf-framerate = <0x78>;
			mi,mdss-dsi-ddic-mode = "auto";
			mi,mdss-dc-status-control-dc-6C-cfg = <0x02 0x00>;
			qcom,mdss-dsi-h-sync-skew = <0xbc01>;
			qcom,mdss-dsi-panel-framerate = <0x78>;
			cell-index = <0x05>;
			qcom,src-chroma-format = <0x01>;
			qcom,mdss-dsc-block-prediction-enable;
			qcom,mdss-dsc-bit-per-pixel = <0x08>;
			qcom,mdss-dsc-bit-per-component = <0x0a>;
			qcom,mdss-dsc-slice-per-pkt = <0x02>;
			qcom,mdss-dsc-slice-width = <0x258>;
			qcom,mdss-dsc-slice-height = <0x1e>;
			qcom,mdss-dsc-scr-version = <0x00>;
			qcom,mdss-dsc-version = <0x12>;
			qcom,compression-mode = "dsc";
			qcom,default-topology-index = <0x00>;
			qcom,display-topology = <0x02 0x02 0x01>;
			qcom,mdss-dsi-panel-phy-timings = [00 26 0a 0a 1b 19 0a 0a 0a 02 04 00 20 0f];
			qcom,mdss-mdp-transfer-time-us = <7300>;
			qcom,mdss-dsi-panel-jitter = <0x05 0x01>;
			qcom,mdss-dsi-panel-clockrate = <0x448b9b80>;
			qcom,mdss-dsi-v-bottom-border = <0x00>;
			qcom,mdss-dsi-v-top-border = <0x00>;
			qcom,mdss-dsi-h-right-border = <0x00>;
			qcom,mdss-dsi-h-left-border = <0x00>;
			qcom,mdss-dsi-h-sync-pulse = <0x00>;
			qcom,mdss-dsi-v-pulse-width = <0x08>;
			qcom,mdss-dsi-v-front-porch = <0x2d>;
			qcom,mdss-dsi-v-back-porch = <0x25>;
			qcom,mdss-dsi-h-pulse-width = <0x10>;
			qcom,mdss-dsi-h-back-porch = <0x20>;
			qcom,mdss-dsi-h-front-porch = <0x10>;
			qcom,mdss-dsi-panel-height = <0xa6e>;
			qcom,mdss-dsi-panel-width = <0x4b0>;
			mi,mdss-dsi-dimmingoff-command-state = "dsi_hs_mode";
			mi,mdss-dsi-dimmingoff-command = [15 00 00 00 00 00 02 53 20];
			mi,mdss-dsi-dimmingon-command-state = "dsi_hs_mode";
			mi,mdss-dsi-dimmingon-command = [15 00 00 00 00 00 02 53 28];
			mi,mdss-dsi-auto-current-limit-command-update = <0xc1 0x01 0x02>;
			mi,mdss-dsi-auto-current-limit-command-state = "dsi_lp_mode";
			mi,mdss-dsi-auto-current-limit-command = <0x39000040 0x3f0 0xaa113900 0x00 0x3c103ff>;
			mi,mdss-dsi-round-corner-off-command-state = "dsi_lp_mode";
			mi,mdss-dsi-round-corner-off-command = [39 00 00 40 00 00 03 f0 aa 18 15 00 00 00 00 00 02 b0 00];
			mi,mdss-dsi-round-corner-on-command-state = "dsi_lp_mode";
			mi,mdss-dsi-round-corner-on-command = [39 00 00 40 00 00 03 f0 aa 18 15 00 00 00 00 00 02 b0 80];
			mi,mdss-dsi-doze-lbm-nolp-command-state = "dsi_lp_mode";
			mi,mdss-dsi-doze-hbm-nolp-command-state = "dsi_lp_mode";
			mi,mdss-dsi-doze-lbm-nolp-command = [05 00 00 40 00 00 01 38 15 00 00 40 00 00 02 75 00 39 00 00 40 00 00 03 f0 aa 1b 15 00 00 40 00 00 02 d0 00 39 00 00 40 00 00 03 51 00 14 39 00 00 40 00 00 03 f0 aa 10 15 00 00 00 00 00 02 cf 16];
			mi,mdss-dsi-doze-hbm-nolp-command = [05 00 00 40 00 00 01 38 15 00 00 40 00 00 02 75 00 39 00 00 40 00 00 03 f0 aa 1b 15 00 00 40 00 00 02 d0 00 39 00 00 40 00 00 03 51 00 ee 39 00 00 40 00 00 03 f0 aa 10 15 00 00 00 00 00 02 cf 16];
			mi,mdss-dsi-doze-lbm-command-state = "dsi_lp_mode";
			mi,mdss-dsi-doze-lbm-command = [39 00 00 40 00 00 03 f0 aa 1b 15 00 00 40 00 00 02 d0 00 15 00 00 40 00 00 02 75 00 15 00 00 00 09 00 02 71 00 39 00 00 40 00 00 03 f0 aa 1b 39 00 00 40 00 00 0e d2 04 01 03 04 0b 0b 0b 0b 0b 00 0e e0 00 15 00 00 40 00 00 02 d0 11 05 00 00 40 00 00 01 39 15 00 00 40 00 00 02 6d 02 15 00 00 40 00 00 02 75 01 39 00 00 40 00 00 03 f0 aa 10 15 00 00 40 00 00 02 cf 09 15 00 00 40 00 00 02 53 20 39 00 00 00 00 00 03 51 00 12];
			mi,mdss-dsi-doze-hbm-command-state = "dsi_lp_mode";
			mi,mdss-dsi-doze-hbm-command = [39 00 00 40 00 00 03 f0 aa 1b 15 00 00 40 00 00 02 d0 00 15 00 00 40 00 00 02 75 00 15 00 00 00 09 00 02 71 00 39 00 00 40 00 00 03 f0 aa 1b 39 00 00 40 00 00 0e d2 04 01 03 04 0b 0b 0b 0b 0b 00 0e e0 00 15 00 00 40 00 00 02 d0 11 05 00 00 40 00 00 01 39 15 00 00 40 00 00 02 6d 00 15 00 00 40 00 00 02 75 01 39 00 00 40 00 00 03 f0 aa 10 15 00 00 40 00 00 02 cf 09 15 00 00 40 00 00 02 53 20 39 00 00 00 00 00 03 51 00 cf];
			mi,mdss-dsi-hbm-off-command-state = "dsi_hs_mode";
			mi,mdss-dsi-hbm-off-command = [39 00 00 40 00 00 03 f0 aa 10 15 00 00 40 00 00 02 65 01 15 00 00 40 00 00 02 d0 04 39 00 00 00 00 00 03 51 0a ab];
			mi,mdss-dsi-hbm-on-command-state = "dsi_hs_mode";
			mi,mdss-dsi-hbm-on-command = [39 00 00 40 00 00 03 f0 aa 10 15 00 00 40 00 00 02 65 01 15 00 00 40 00 00 02 d0 05 39 00 00 00 00 00 03 51 17 ff];
			mi,mdss-dsi-vint-off-command-state = "dsi_lp_mode";
			mi,mdss-dsi-vint-off-command = [39 00 00 40 00 00 03 f0 aa 12 39 00 00 40 00 00 02 bf 63 39 00 00 40 00 00 02 65 30 39 00 00 40 00 00 02 bf 63 39 00 00 40 00 00 02 d9 63 39 00 00 40 00 00 02 65 30 39 00 00 40 00 00 02 d9 63 39 00 00 40 00 00 02 df 63 39 00 00 40 00 00 02 65 30 39 00 00 40 00 00 02 df 63 39 00 00 40 00 00 02 eb 63 39 00 00 40 00 00 02 65 30 39 00 00 00 00 00 02 eb 63];
			qcom,mdss-dsi-off-command-state = "dsi_hs_mode";
			qcom,mdss-dsi-off-command = <0x5000000 0x128 0x5000000 0x78000110>;
		};

		timing@idle_120_to_10hz_index_06 {
			mi,mdss-dsi-dc-off-command-state = "dsi_lp_mode";
			mi,mdss-dsi-dc-off-command = [15 00 00 00 00 00 02 6c 00];
			mi,mdss-dsi-dc-on-command-state = "dsi_lp_mode";
			mi,mdss-dsi-dc-on-command = [15 00 00 00 00 00 02 6c 02];
			qcom,mdss-dsi-nolp-command-state = "dsi_lp_mode";
			qcom,mdss-dsi-nolp-command-update = <0x51 0x0b 0x02 0x6c 0x01 0x01>;
			qcom,mdss-dsi-nolp-command = <0x5000040 0x138 0x15000040 0x26c 0x2150000 0x40000002 0x71001500 0x400000 0x2750139 0x4000 0x3f0aa 0x1b150000 0x40000002 0x650c3900 0x400000 0x5d50b0b 0xb0b1500 0x400000 0x2650c39 0x4000 0x5d70b 0xb0b0b39 0x4000 0xed202 0x103040b 0x7090b00 0x00 0x15000040 0x2d0 0x11390000 0x40000003 0x51000039 0x4000 0x3f0aa 0x10150000 0x90002 0xcf093900 0x00 0x3f0aa00>;
			qcom,mdss-dsi-timing-switch-command-state = "dsi_lp_mode";
			qcom,mdss-dsi-timing-switch-command = [15 00 00 40 00 00 02 71 00 15 00 00 40 00 00 02 75 01 39 00 00 40 00 00 03 f0 aa 1b 15 00 00 40 00 00 02 65 0c 39 00 00 40 00 00 05 d5 0b 0b 0b 0b 15 00 00 40 00 00 02 65 0c 39 00 00 40 00 00 05 d7 0b 0b 0b 0b 39 00 00 40 00 00 0e d2 02 01 03 04 0b 07 09 0b 00 00 00 00 00 15 00 00 40 00 00 02 d0 11 39 00 00 40 00 00 03 f0 aa 10 15 00 00 00 00 00 02 cf 09];
			mi,mdss-dsi-timing-switch-from-normal-mode-command-state = "dsi_lp_mode";
			mi,mdss-dsi-timing-switch-from-normal-mode-command-update = <0x6c 0x00 0x01>;
			mi,mdss-dsi-timing-switch-from-normal-mode-command = [15 00 00 00 00 00 02 6c 00];
			mi,mdss-dsi-timing-switch-from-skip-mode-command-state = "dsi_lp_mode";
			mi,mdss-dsi-timing-switch-from-skip-mode-command-update = <0x6c 0x01 0x01>;
			mi,mdss-dsi-timing-switch-from-skip-mode-command = [15 00 00 40 00 00 02 71 00 15 00 00 00 0a 00 02 6c 00];
			mi,mdss-dsi-timing-switch-from-auto-mode-command-state = "dsi_lp_mode";
			mi,mdss-dsi-timing-switch-from-auto-mode-command-update = <0x6c 0x01 0x01>;
			mi,mdss-dsi-timing-switch-from-auto-mode-command = [15 00 00 40 00 00 02 71 00 15 00 00 40 00 00 02 6c 02 39 00 00 40 00 00 03 f0 aa 1b 15 00 00 40 00 00 02 d0 00 15 00 00 00 0a 00 02 75 00];
			qcom,mdss-dsi-on-command-state = "dsi_lp_mode";
			qcom,mdss-dsi-on-command = [39 00 00 40 00 00 03 f0 aa 10 15 00 00 40 00 00 02 65 01 15 00 00 40 00 00 02 d0 05 15 00 00 40 00 00 02 03 01 15 00 00 40 00 00 02 35 00 15 00 00 40 00 00 02 53 28 39 00 00 40 00 00 03 f0 aa 13 15 00 00 40 00 00 02 c8 10 15 00 00 40 00 00 02 d0 10 15 00 00 40 00 00 02 e0 10 15 00 00 40 00 00 02 e8 10 39 00 00 40 00 00 03 51 00 00 15 00 00 40 00 00 02 5e 00 15 00 00 40 00 00 02 59 09 39 00 00 40 00 00 03 ff 5a 81 15 00 00 40 00 00 02 65 1b 15 00 00 40 00 00 02 f8 04 15 00 00 40 00 00 02 65 1a 15 00 00 40 00 00 02 f8 0f 15 00 00 40 00 00 02 65 0a 15 00 00 00 00 00 02 f8 fb 15 00 00 40 00 00 02 6c 02 15 00 00 40 00 00 02 71 00 15 00 00 40 00 00 02 75 01 39 00 00 40 00 00 03 f0 aa 1b 15 00 00 40 00 00 02 65 0c 39 00 00 40 00 00 05 d5 0b 0b 0b 0b 15 00 00 40 00 00 02 65 0c 39 00 00 40 00 00 05 d7 0b 0b 0b 0b 39 00 00 40 00 00 0e d2 02 01 03 04 0b 07 09 0b 00 00 00 00 00 15 00 00 40 00 00 02 d0 11 39 00 00 40 00 00 03 f0 aa 10 15 00 00 00 00 00 02 cf 09 15 00 00 40 00 00 02 6d 00 15 00 00 40 00 00 02 6f 02 15 00 00 40 00 00 02 72 00 39 00 00 00 00 00 60 70 12 00 00 ab 21 00 0a 6e 04 b0 00 1e 02 58 02 58 01 55 01 d2 00 0a 01 88 00 32 00 0d 03 97 11 48 08 00 0c 00 07 10 20 00 06 0f 0f 33 0e 1c 2a 38 46 54 62 69 70 77 79 7b 7d 7e 00 82 11 40 19 c0 22 3e 32 7c 3a ba 3a f8 3b 38 3b 38 3b 76 4b 76 4b 74 4b 74 5b b4 73 f4 01 00 00 00 00 00 00 39 00 00 40 00 00 03 f0 aa 10 39 00 00 40 00 00 0e bd 10 02 31 46 75 8a b9 01 32 45 76 89 ba 39 00 00 40 00 00 03 f0 aa 17 15 00 00 40 00 00 02 b0 11 39 00 00 40 00 00 07 c0 21 00 34 20 31 04 15 00 00 40 00 00 02 65 06 15 00 00 40 00 00 02 bf ff 39 00 00 40 00 00 03 ff 5a 80 15 00 00 40 00 00 02 65 0a 39 00 00 40 00 00 03 f9 9e 8f 15 00 00 40 00 00 02 65 0f 15 00 00 40 00 00 02 f9 14 39 00 00 40 00 00 03 ff 5a 81 15 00 00 40 00 00 02 65 03 15 00 00 40 00 00 02 f3 24 15 00 00 40 00 00 02 65 05 15 00 00 40 00 00 02 f3 a0 39 00 00 40 00 00 03 ff 5a 81 15 00 00 40 00 00 02 65 02 39 00 00 40 00 00 05 fb d3 d3 d3 d3 39 00 00 40 00 00 03 f0 aa 10 15 00 00 40 00 00 02 65 04 15 00 00 00 00 00 02 cf 4b 39 00 00 40 00 00 03 f0 aa 10 15 00 00 40 00 00 02 65 01 15 00 00 00 00 00 02 cf 07 39 00 00 40 00 00 03 f0 aa 10 15 00 00 40 00 00 02 65 03 15 00 00 00 00 00 02 cf 24 39 00 00 40 00 00 03 f0 aa 10 15 00 00 40 00 00 02 b6 00 39 00 00 40 00 00 03 ff 5a 82 15 00 00 40 00 00 02 65 04 15 00 00 00 00 00 02 f8 10 39 00 00 40 00 00 03 f0 aa 11 15 00 00 40 00 00 02 c0 00 15 00 00 40 00 00 02 65 09 39 00 00 40 00 00 04 c0 55 aa aa 39 00 00 40 00 00 0c c1 03 34 03 99 03 34 03 ff ff a6 00 15 00 00 40 00 00 02 55 01 39 00 00 40 00 00 03 f0 aa 10 15 00 00 40 00 00 02 65 07 15 00 00 40 00 00 02 d0 00 15 00 00 40 00 00 02 65 09 39 00 00 40 00 00 03 d0 03 19 15 00 00 40 00 00 02 65 0c 15 00 00 40 00 00 02 d0 00 15 00 00 40 00 00 02 65 0e 39 00 00 40 00 00 03 d0 03 19 15 00 00 40 00 00 02 65 11 15 00 00 40 00 00 02 d0 19 39 00 00 40 00 00 03 f0 aa 12 15 00 00 40 00 00 02 65 0b 15 00 00 40 00 00 02 d2 10 39 00 00 40 00 00 03 f0 aa 10 39 00 00 00 00 00 09 c4 34 34 34 34 34 34 34 34 39 00 00 40 00 00 03 f0 aa 12 15 00 00 40 00 00 02 d6 00 15 00 00 40 00 00 02 65 02 15 00 00 00 00 00 02 d1 00 39 00 00 40 00 00 03 5f 04 7e 39 00 00 40 00 00 03 f0 aa 12 39 00 00 40 00 00 20 c3 e1 20 30 01 cd 01 cd 01 cd 01 cd 01 cd 01 cd 01 cd 00 64 00 64 00 64 00 64 00 64 00 64 00 64 39 00 00 40 00 00 03 ff 5a 81 15 00 00 40 00 00 02 65 15 15 00 00 00 00 00 02 fc 7e 05 00 00 00 78 00 01 11 05 00 00 00 00 00 01 29];
			mi,mdss-dc-status-control-dc-6C-cfg = <0x02 0x00>;
			qcom,dsi-mode-te-width-us = <245>;
			mi,mdss-dsi-ddic-min-framerate = <0x0a>;
			mi,mdss-dsi-sf-framerate = <0x78>;
			mi,mdss-dsi-ddic-mode = "idle";
			qcom,mdss-dsi-h-sync-skew = <0x7c0a>;
			qcom,mdss-dsi-panel-framerate = <0x78>;
			cell-index = <0x06>;
			qcom,src-chroma-format = <0x01>;
			qcom,mdss-dsc-block-prediction-enable;
			qcom,mdss-dsc-bit-per-pixel = <0x08>;
			qcom,mdss-dsc-bit-per-component = <0x0a>;
			qcom,mdss-dsc-slice-per-pkt = <0x02>;
			qcom,mdss-dsc-slice-width = <0x258>;
			qcom,mdss-dsc-slice-height = <0x1e>;
			qcom,mdss-dsc-scr-version = <0x00>;
			qcom,mdss-dsc-version = <0x12>;
			qcom,compression-mode = "dsc";
			qcom,default-topology-index = <0x00>;
			qcom,display-topology = <0x02 0x02 0x01>;
			qcom,mdss-dsi-panel-phy-timings = [00 26 0a 0a 1b 19 0a 0a 0a 02 04 00 20 0f];
			qcom,mdss-mdp-transfer-time-us = <7300>;
			qcom,mdss-dsi-panel-jitter = <0x05 0x01>;
			qcom,mdss-dsi-panel-clockrate = <0x448b9b80>;
			qcom,mdss-dsi-v-bottom-border = <0x00>;
			qcom,mdss-dsi-v-top-border = <0x00>;
			qcom,mdss-dsi-h-right-border = <0x00>;
			qcom,mdss-dsi-h-left-border = <0x00>;
			qcom,mdss-dsi-h-sync-pulse = <0x00>;
			qcom,mdss-dsi-v-pulse-width = <0x08>;
			qcom,mdss-dsi-v-front-porch = <0x2d>;
			qcom,mdss-dsi-v-back-porch = <0x25>;
			qcom,mdss-dsi-h-pulse-width = <0x10>;
			qcom,mdss-dsi-h-back-porch = <0x20>;
			qcom,mdss-dsi-h-front-porch = <0x10>;
			qcom,mdss-dsi-panel-height = <0xa6e>;
			qcom,mdss-dsi-panel-width = <0x4b0>;
			mi,mdss-dsi-dimmingoff-command-state = "dsi_hs_mode";
			mi,mdss-dsi-dimmingoff-command = [15 00 00 00 00 00 02 53 20];
			mi,mdss-dsi-dimmingon-command-state = "dsi_hs_mode";
			mi,mdss-dsi-dimmingon-command = [15 00 00 00 00 00 02 53 28];
			mi,mdss-dsi-auto-current-limit-command-update = <0xc1 0x01 0x02>;
			mi,mdss-dsi-auto-current-limit-command-state = "dsi_lp_mode";
			mi,mdss-dsi-auto-current-limit-command = <0x39000040 0x3f0 0xaa113900 0x00 0x3c103ff>;
			mi,mdss-dsi-round-corner-off-command-state = "dsi_lp_mode";
			mi,mdss-dsi-round-corner-off-command = [39 00 00 40 00 00 03 f0 aa 18 15 00 00 00 00 00 02 b0 00];
			mi,mdss-dsi-round-corner-on-command-state = "dsi_lp_mode";
			mi,mdss-dsi-round-corner-on-command = [39 00 00 40 00 00 03 f0 aa 18 15 00 00 00 00 00 02 b0 80];
			mi,mdss-dsi-doze-lbm-nolp-command-state = "dsi_lp_mode";
			mi,mdss-dsi-doze-hbm-nolp-command-state = "dsi_lp_mode";
			mi,mdss-dsi-doze-lbm-nolp-command = [05 00 00 40 00 00 01 38 15 00 00 40 00 00 02 75 00 39 00 00 40 00 00 03 f0 aa 1b 15 00 00 40 00 00 02 d0 00 39 00 00 40 00 00 03 51 00 14 39 00 00 40 00 00 03 f0 aa 10 15 00 00 00 00 00 02 cf 16];
			mi,mdss-dsi-doze-hbm-nolp-command = [05 00 00 40 00 00 01 38 15 00 00 40 00 00 02 75 00 39 00 00 40 00 00 03 f0 aa 1b 15 00 00 40 00 00 02 d0 00 39 00 00 40 00 00 03 51 00 ee 39 00 00 40 00 00 03 f0 aa 10 15 00 00 00 00 00 02 cf 16];
			mi,mdss-dsi-doze-lbm-command-state = "dsi_lp_mode";
			mi,mdss-dsi-doze-lbm-command = [39 00 00 40 00 00 03 f0 aa 1b 15 00 00 40 00 00 02 d0 00 15 00 00 40 00 00 02 75 00 15 00 00 00 09 00 02 71 00 39 00 00 40 00 00 03 f0 aa 1b 39 00 00 40 00 00 0e d2 04 01 03 04 0b 0b 0b 0b 0b 00 0e e0 00 15 00 00 40 00 00 02 d0 11 05 00 00 40 00 00 01 39 15 00 00 40 00 00 02 6d 02 15 00 00 40 00 00 02 75 01 39 00 00 40 00 00 03 f0 aa 10 15 00 00 40 00 00 02 cf 09 15 00 00 40 00 00 02 53 20 39 00 00 00 00 00 03 51 00 12];
			mi,mdss-dsi-doze-hbm-command-state = "dsi_lp_mode";
			mi,mdss-dsi-doze-hbm-command = [39 00 00 40 00 00 03 f0 aa 1b 15 00 00 40 00 00 02 d0 00 15 00 00 40 00 00 02 75 00 15 00 00 00 09 00 02 71 00 39 00 00 40 00 00 03 f0 aa 1b 39 00 00 40 00 00 0e d2 04 01 03 04 0b 0b 0b 0b 0b 00 0e e0 00 15 00 00 40 00 00 02 d0 11 05 00 00 40 00 00 01 39 15 00 00 40 00 00 02 6d 00 15 00 00 40 00 00 02 75 01 39 00 00 40 00 00 03 f0 aa 10 15 00 00 40 00 00 02 cf 09 15 00 00 40 00 00 02 53 20 39 00 00 00 00 00 03 51 00 cf];
			mi,mdss-dsi-hbm-off-command-state = "dsi_hs_mode";
			mi,mdss-dsi-hbm-off-command = [39 00 00 40 00 00 03 f0 aa 10 15 00 00 40 00 00 02 65 01 15 00 00 40 00 00 02 d0 04 39 00 00 00 00 00 03 51 0a ab];
			mi,mdss-dsi-hbm-on-command-state = "dsi_hs_mode";
			mi,mdss-dsi-hbm-on-command = [39 00 00 40 00 00 03 f0 aa 10 15 00 00 40 00 00 02 65 01 15 00 00 40 00 00 02 d0 05 39 00 00 00 00 00 03 51 17 ff];
			mi,mdss-dsi-vint-off-command-state = "dsi_lp_mode";
			mi,mdss-dsi-vint-off-command = [39 00 00 40 00 00 03 f0 aa 12 39 00 00 40 00 00 02 bf 63 39 00 00 40 00 00 02 65 30 39 00 00 40 00 00 02 bf 63 39 00 00 40 00 00 02 d9 63 39 00 00 40 00 00 02 65 30 39 00 00 40 00 00 02 d9 63 39 00 00 40 00 00 02 df 63 39 00 00 40 00 00 02 65 30 39 00 00 40 00 00 02 df 63 39 00 00 40 00 00 02 eb 63 39 00 00 40 00 00 02 65 30 39 00 00 00 00 00 02 eb 63];
			qcom,mdss-dsi-off-command-state = "dsi_hs_mode";
			qcom,mdss-dsi-off-command = <0x5000000 0x128 0x5000000 0x78000110>;
		};

		timing@idle_120_to_1hz_index_07 {
			mi,mdss-dsi-dc-off-command-state = "dsi_lp_mode";
			mi,mdss-dsi-dc-off-command = [15 00 00 00 00 00 02 6c 00];
			mi,mdss-dsi-dc-on-command-state = "dsi_lp_mode";
			mi,mdss-dsi-dc-on-command = [15 00 00 00 00 00 02 6c 02];
			qcom,mdss-dsi-nolp-command-state = "dsi_lp_mode";
			qcom,mdss-dsi-nolp-command-update = <0x51 0x0b 0x02 0x6c 0x01 0x01>;
			qcom,mdss-dsi-nolp-command = <0x5000040 0x138 0x15000040 0x26c 0x2150000 0x40000002 0x71001500 0x400000 0x2750139 0x4000 0x3f0aa 0x1b150000 0x40000002 0x650c3900 0x400000 0x5d57777 0x77771500 0x400000 0x2650c39 0x4000 0x5d777 0x77777739 0x4000 0xed204 0x103040b 0xb0b0b0b 0xee000 0x15000040 0x2d0 0x11390000 0x40000003 0x51000039 0x4000 0x3f0aa 0x10150000 0x90002 0xcf093900 0x00 0x3f0aa00>;
			qcom,mdss-dsi-timing-switch-command-state = "dsi_lp_mode";
			qcom,mdss-dsi-timing-switch-command = [15 00 00 40 00 00 02 71 00 15 00 00 40 00 00 02 75 01 39 00 00 40 00 00 03 f0 aa 1b 15 00 00 40 00 00 02 65 0c 39 00 00 40 00 00 05 d5 77 77 77 77 15 00 00 40 00 00 02 65 0c 39 00 00 40 00 00 05 d7 77 77 77 77 39 00 00 40 00 00 0e d2 04 01 03 04 0b 0b 0b 0b 0b 00 0e e0 00 15 00 00 40 00 00 02 d0 11 39 00 00 40 00 00 03 f0 aa 10 15 00 00 00 00 00 02 cf 09];
			mi,mdss-dsi-timing-switch-from-normal-mode-command-state = "dsi_lp_mode";
			mi,mdss-dsi-timing-switch-from-normal-mode-command-update = <0x6c 0x00 0x01>;
			mi,mdss-dsi-timing-switch-from-normal-mode-command = [15 00 00 00 00 00 02 6c 00];
			mi,mdss-dsi-timing-switch-from-skip-mode-command-state = "dsi_lp_mode";
			mi,mdss-dsi-timing-switch-from-skip-mode-command-update = <0x6c 0x01 0x01>;
			mi,mdss-dsi-timing-switch-from-skip-mode-command = [15 00 00 40 00 00 02 71 00 15 00 00 00 0a 00 02 6c 00];
			mi,mdss-dsi-timing-switch-from-auto-mode-command-state = "dsi_lp_mode";
			mi,mdss-dsi-timing-switch-from-auto-mode-command-update = <0x6c 0x01 0x01>;
			mi,mdss-dsi-timing-switch-from-auto-mode-command = [15 00 00 40 00 00 02 71 00 15 00 00 40 00 00 02 6c 02 39 00 00 40 00 00 03 f0 aa 1b 15 00 00 40 00 00 02 d0 00 15 00 00 00 0a 00 02 75 00];
			qcom,mdss-dsi-on-command-state = "dsi_lp_mode";
			qcom,mdss-dsi-on-command = [39 00 00 40 00 00 03 f0 aa 10 15 00 00 40 00 00 02 65 01 15 00 00 40 00 00 02 d0 05 15 00 00 40 00 00 02 03 01 15 00 00 40 00 00 02 35 00 15 00 00 40 00 00 02 53 28 39 00 00 40 00 00 03 f0 aa 13 15 00 00 40 00 00 02 c8 10 15 00 00 40 00 00 02 d0 10 15 00 00 40 00 00 02 e0 10 15 00 00 40 00 00 02 e8 10 39 00 00 40 00 00 03 51 00 00 15 00 00 40 00 00 02 5e 00 15 00 00 40 00 00 02 59 09 39 00 00 40 00 00 03 ff 5a 81 15 00 00 40 00 00 02 65 1b 15 00 00 40 00 00 02 f8 04 15 00 00 40 00 00 02 65 1a 15 00 00 40 00 00 02 f8 0f 15 00 00 40 00 00 02 65 0a 15 00 00 00 00 00 02 f8 fb 15 00 00 40 00 00 02 6c 02 15 00 00 40 00 00 02 71 00 15 00 00 40 00 00 02 75 01 39 00 00 40 00 00 03 f0 aa 1b 15 00 00 40 00 00 02 65 0c 39 00 00 40 00 00 05 d5 77 77 77 77 15 00 00 40 00 00 02 65 0c 39 00 00 40 00 00 05 d7 77 77 77 77 39 00 00 40 00 00 0e d2 04 01 03 04 0b 0b 0b 0b 0b 00 0e e0 00 15 00 00 40 00 00 02 d0 11 39 00 00 40 00 00 03 f0 aa 10 15 00 00 00 00 00 02 cf 09 15 00 00 40 00 00 02 6d 00 15 00 00 40 00 00 02 6f 02 15 00 00 40 00 00 02 72 00 39 00 00 00 00 00 60 70 12 00 00 ab 21 00 0a 6e 04 b0 00 1e 02 58 02 58 01 55 01 d2 00 0a 01 88 00 32 00 0d 03 97 11 48 08 00 0c 00 07 10 20 00 06 0f 0f 33 0e 1c 2a 38 46 54 62 69 70 77 79 7b 7d 7e 00 82 11 40 19 c0 22 3e 32 7c 3a ba 3a f8 3b 38 3b 38 3b 76 4b 76 4b 74 4b 74 5b b4 73 f4 01 00 00 00 00 00 00 39 00 00 40 00 00 03 f0 aa 10 39 00 00 40 00 00 0e bd 10 02 31 46 75 8a b9 01 32 45 76 89 ba 39 00 00 40 00 00 03 f0 aa 17 15 00 00 40 00 00 02 b0 11 39 00 00 40 00 00 07 c0 21 00 34 20 31 04 15 00 00 40 00 00 02 65 06 15 00 00 40 00 00 02 bf ff 39 00 00 40 00 00 03 ff 5a 80 15 00 00 40 00 00 02 65 0a 39 00 00 40 00 00 03 f9 9e 8f 15 00 00 40 00 00 02 65 0f 15 00 00 40 00 00 02 f9 14 39 00 00 40 00 00 03 ff 5a 81 15 00 00 40 00 00 02 65 03 15 00 00 40 00 00 02 f3 24 15 00 00 40 00 00 02 65 05 15 00 00 40 00 00 02 f3 a0 39 00 00 40 00 00 03 ff 5a 81 15 00 00 40 00 00 02 65 02 39 00 00 40 00 00 05 fb d3 d3 d3 d3 39 00 00 40 00 00 03 f0 aa 10 15 00 00 40 00 00 02 65 04 15 00 00 00 00 00 02 cf 4b 39 00 00 40 00 00 03 f0 aa 10 15 00 00 40 00 00 02 65 01 15 00 00 00 00 00 02 cf 07 39 00 00 40 00 00 03 f0 aa 10 15 00 00 40 00 00 02 65 03 15 00 00 00 00 00 02 cf 24 39 00 00 40 00 00 03 f0 aa 10 15 00 00 40 00 00 02 b6 00 39 00 00 40 00 00 03 ff 5a 82 15 00 00 40 00 00 02 65 04 15 00 00 00 00 00 02 f8 10 39 00 00 40 00 00 03 f0 aa 11 15 00 00 40 00 00 02 c0 00 15 00 00 40 00 00 02 65 09 39 00 00 40 00 00 04 c0 55 aa aa 39 00 00 40 00 00 0c c1 03 34 03 99 03 34 03 ff ff a6 00 15 00 00 40 00 00 02 55 01 39 00 00 40 00 00 03 f0 aa 10 15 00 00 40 00 00 02 65 07 15 00 00 40 00 00 02 d0 00 15 00 00 40 00 00 02 65 09 39 00 00 40 00 00 03 d0 03 19 15 00 00 40 00 00 02 65 0c 15 00 00 40 00 00 02 d0 00 15 00 00 40 00 00 02 65 0e 39 00 00 40 00 00 03 d0 03 19 15 00 00 40 00 00 02 65 11 15 00 00 40 00 00 02 d0 19 39 00 00 40 00 00 03 f0 aa 12 15 00 00 40 00 00 02 65 0b 15 00 00 40 00 00 02 d2 10 39 00 00 40 00 00 03 f0 aa 10 39 00 00 00 00 00 09 c4 34 34 34 34 34 34 34 34 39 00 00 40 00 00 03 f0 aa 12 15 00 00 40 00 00 02 d6 00 15 00 00 40 00 00 02 65 02 15 00 00 00 00 00 02 d1 00 39 00 00 40 00 00 03 5f 04 7e 39 00 00 40 00 00 03 f0 aa 12 39 00 00 40 00 00 20 c3 e1 20 30 01 cd 01 cd 01 cd 01 cd 01 cd 01 cd 01 cd 00 64 00 64 00 64 00 64 00 64 00 64 00 64 39 00 00 40 00 00 03 ff 5a 81 15 00 00 40 00 00 02 65 15 15 00 00 00 00 00 02 fc 7e 05 00 00 00 78 00 01 11 05 00 00 00 00 00 01 29];
			qcom,dsi-mode-te-width-us = <245>;
			mi,mdss-dsi-ddic-min-framerate = <0x01>;
			mi,mdss-dsi-sf-framerate = <0x78>;
			mi,mdss-dsi-ddic-mode = "idle";
			mi,mdss-dc-status-control-dc-6C-cfg = <0x02 0x00>;
			qcom,mdss-dsi-h-sync-skew = <0x7c01>;
			qcom,mdss-dsi-panel-framerate = <0x78>;
			cell-index = <0x07>;
			qcom,src-chroma-format = <0x01>;
			qcom,mdss-dsc-block-prediction-enable;
			qcom,mdss-dsc-bit-per-pixel = <0x08>;
			qcom,mdss-dsc-bit-per-component = <0x0a>;
			qcom,mdss-dsc-slice-per-pkt = <0x02>;
			qcom,mdss-dsc-slice-width = <0x258>;
			qcom,mdss-dsc-slice-height = <0x1e>;
			qcom,mdss-dsc-scr-version = <0x00>;
			qcom,mdss-dsc-version = <0x12>;
			qcom,compression-mode = "dsc";
			qcom,default-topology-index = <0x00>;
			qcom,display-topology = <0x02 0x02 0x01>;
			qcom,mdss-dsi-panel-phy-timings = [00 26 0a 0a 1b 19 0a 0a 0a 02 04 00 20 0f];
			qcom,mdss-mdp-transfer-time-us = <7300>;
			qcom,mdss-dsi-panel-jitter = <0x05 0x01>;
			qcom,mdss-dsi-panel-clockrate = <0x448b9b80>;
			qcom,mdss-dsi-v-bottom-border = <0x00>;
			qcom,mdss-dsi-v-top-border = <0x00>;
			qcom,mdss-dsi-h-right-border = <0x00>;
			qcom,mdss-dsi-h-left-border = <0x00>;
			qcom,mdss-dsi-h-sync-pulse = <0x00>;
			qcom,mdss-dsi-v-pulse-width = <0x08>;
			qcom,mdss-dsi-v-front-porch = <0x2d>;
			qcom,mdss-dsi-v-back-porch = <0x25>;
			qcom,mdss-dsi-h-pulse-width = <0x10>;
			qcom,mdss-dsi-h-back-porch = <0x20>;
			qcom,mdss-dsi-h-front-porch = <0x10>;
			qcom,mdss-dsi-panel-height = <0xa6e>;
			qcom,mdss-dsi-panel-width = <0x4b0>;
			mi,mdss-dsi-dimmingoff-command-state = "dsi_hs_mode";
			mi,mdss-dsi-dimmingoff-command = [15 00 00 00 00 00 02 53 20];
			mi,mdss-dsi-dimmingon-command-state = "dsi_hs_mode";
			mi,mdss-dsi-dimmingon-command = [15 00 00 00 00 00 02 53 28];
			mi,mdss-dsi-auto-current-limit-command-update = <0xc1 0x01 0x02>;
			mi,mdss-dsi-auto-current-limit-command-state = "dsi_lp_mode";
			mi,mdss-dsi-auto-current-limit-command = <0x39000040 0x3f0 0xaa113900 0x00 0x3c103ff>;
			mi,mdss-dsi-round-corner-off-command-state = "dsi_lp_mode";
			mi,mdss-dsi-round-corner-off-command = [39 00 00 40 00 00 03 f0 aa 18 15 00 00 00 00 00 02 b0 00];
			mi,mdss-dsi-round-corner-on-command-state = "dsi_lp_mode";
			mi,mdss-dsi-round-corner-on-command = [39 00 00 40 00 00 03 f0 aa 18 15 00 00 00 00 00 02 b0 80];
			mi,mdss-dsi-doze-lbm-nolp-command-state = "dsi_lp_mode";
			mi,mdss-dsi-doze-hbm-nolp-command-state = "dsi_lp_mode";
			mi,mdss-dsi-doze-lbm-nolp-command = [05 00 00 40 00 00 01 38 15 00 00 40 00 00 02 75 00 39 00 00 40 00 00 03 f0 aa 1b 15 00 00 40 00 00 02 d0 00 39 00 00 40 00 00 03 51 00 14 39 00 00 40 00 00 03 f0 aa 10 15 00 00 00 00 00 02 cf 16];
			mi,mdss-dsi-doze-hbm-nolp-command = [05 00 00 40 00 00 01 38 15 00 00 40 00 00 02 75 00 39 00 00 40 00 00 03 f0 aa 1b 15 00 00 40 00 00 02 d0 00 39 00 00 40 00 00 03 51 00 ee 39 00 00 40 00 00 03 f0 aa 10 15 00 00 00 00 00 02 cf 16];
			mi,mdss-dsi-doze-lbm-command-state = "dsi_lp_mode";
			mi,mdss-dsi-doze-lbm-command = [39 00 00 40 00 00 03 f0 aa 1b 15 00 00 40 00 00 02 d0 00 15 00 00 40 00 00 02 75 00 15 00 00 00 09 00 02 71 00 39 00 00 40 00 00 03 f0 aa 1b 39 00 00 40 00 00 0e d2 04 01 03 04 0b 0b 0b 0b 0b 00 0e e0 00 15 00 00 40 00 00 02 d0 11 05 00 00 40 00 00 01 39 15 00 00 40 00 00 02 6d 02 15 00 00 40 00 00 02 75 01 39 00 00 40 00 00 03 f0 aa 10 15 00 00 40 00 00 02 cf 09 15 00 00 40 00 00 02 53 20 39 00 00 00 00 00 03 51 00 12];
			mi,mdss-dsi-doze-hbm-command-state = "dsi_lp_mode";
			mi,mdss-dsi-doze-hbm-command = [39 00 00 40 00 00 03 f0 aa 1b 15 00 00 40 00 00 02 d0 00 15 00 00 40 00 00 02 75 00 15 00 00 00 09 00 02 71 00 39 00 00 40 00 00 03 f0 aa 1b 39 00 00 40 00 00 0e d2 04 01 03 04 0b 0b 0b 0b 0b 00 0e e0 00 15 00 00 40 00 00 02 d0 11 05 00 00 40 00 00 01 39 15 00 00 40 00 00 02 6d 00 15 00 00 40 00 00 02 75 01 39 00 00 40 00 00 03 f0 aa 10 15 00 00 40 00 00 02 cf 09 15 00 00 40 00 00 02 53 20 39 00 00 00 00 00 03 51 00 cf];
			mi,mdss-dsi-hbm-off-command-state = "dsi_hs_mode";
			mi,mdss-dsi-hbm-off-command = [39 00 00 40 00 00 03 f0 aa 10 15 00 00 40 00 00 02 65 01 15 00 00 40 00 00 02 d0 04 39 00 00 00 00 00 03 51 0a ab];
			mi,mdss-dsi-hbm-on-command-state = "dsi_hs_mode";
			mi,mdss-dsi-hbm-on-command = [39 00 00 40 00 00 03 f0 aa 10 15 00 00 40 00 00 02 65 01 15 00 00 40 00 00 02 d0 05 39 00 00 00 00 00 03 51 17 ff];
			mi,mdss-dsi-vint-off-command-state = "dsi_lp_mode";
			mi,mdss-dsi-vint-off-command = [39 00 00 40 00 00 03 f0 aa 12 39 00 00 40 00 00 02 bf 63 39 00 00 40 00 00 02 65 30 39 00 00 40 00 00 02 bf 63 39 00 00 40 00 00 02 d9 63 39 00 00 40 00 00 02 65 30 39 00 00 40 00 00 02 d9 63 39 00 00 40 00 00 02 df 63 39 00 00 40 00 00 02 65 30 39 00 00 40 00 00 02 df 63 39 00 00 40 00 00 02 eb 63 39 00 00 40 00 00 02 65 30 39 00 00 00 00 00 02 eb 63];
			qcom,mdss-dsi-off-command-state = "dsi_hs_mode";
			qcom,mdss-dsi-off-command = <0x5000000 0x128 0x5000000 0x78000110>;
		};

		timing@normal_90hz_index_08 {
			mi,mdss-dsi-dc-off-command-state = "dsi_lp_mode";
			mi,mdss-dsi-dc-off-command = [15 00 00 00 00 00 02 6c 01];
			mi,mdss-dsi-dc-on-command-state = "dsi_lp_mode";
			mi,mdss-dsi-dc-on-command = [15 00 00 00 00 00 02 6c 03];
			qcom,mdss-dsi-nolp-command-state = "dsi_lp_mode";
			qcom,mdss-dsi-nolp-command-update = <0x51 0x04 0x02 0x6c 0x07 0x01>;
			qcom,mdss-dsi-nolp-command = [05 00 00 40 00 00 01 38 15 00 00 40 00 00 02 75 00 39 00 00 40 00 00 03 f0 aa 1b 15 00 00 40 00 00 02 d0 00 39 00 00 40 00 00 03 51 00 00 39 00 00 40 00 00 03 f0 aa 10 15 00 00 00 09 00 02 cf 16 15 00 00 40 00 00 02 6c 03 15 00 00 40 00 00 02 71 00 39 00 00 00 00 00 03 f0 aa 00];
			qcom,mdss-dsi-timing-switch-command-state = "dsi_lp_mode";
			qcom,mdss-dsi-timing-switch-command-update = <0x6c 0x03 0x01>;
			qcom,mdss-dsi-timing-switch-command = [39 00 00 40 00 00 03 f0 aa 1b 15 00 00 40 00 00 02 d0 00 15 00 00 40 00 00 02 75 00 15 00 00 40 00 00 02 6c 03 15 00 00 40 00 00 02 71 00 39 00 00 40 00 00 03 f0 aa 10 15 00 00 00 00 00 02 cf 16];
			qcom,mdss-dsi-on-command-state = "dsi_lp_mode";
			qcom,mdss-dsi-on-command = [39 00 00 40 00 00 03 f0 aa 10 15 00 00 40 00 00 02 65 01 15 00 00 40 00 00 02 d0 05 15 00 00 40 00 00 02 03 01 15 00 00 40 00 00 02 35 00 15 00 00 40 00 00 02 53 28 39 00 00 40 00 00 03 f0 aa 13 15 00 00 40 00 00 02 c8 10 15 00 00 40 00 00 02 d0 10 15 00 00 40 00 00 02 e0 10 15 00 00 40 00 00 02 e8 10 39 00 00 40 00 00 03 51 00 00 15 00 00 40 00 00 02 5e 00 15 00 00 40 00 00 02 59 09 39 00 00 40 00 00 03 ff 5a 81 15 00 00 40 00 00 02 65 1b 15 00 00 40 00 00 02 f8 04 15 00 00 40 00 00 02 65 1a 15 00 00 40 00 00 02 f8 0f 15 00 00 40 00 00 02 65 0a 15 00 00 00 00 00 02 f8 fb 39 00 00 40 00 00 03 f0 aa 1b 15 00 00 40 00 00 02 d0 00 15 00 00 00 00 00 02 75 00 15 00 00 40 00 00 02 6c 03 39 00 00 40 00 00 03 f0 aa 10 15 00 00 00 00 00 02 cf 16 15 00 00 40 00 00 02 6d 00 15 00 00 40 00 00 02 6f 02 15 00 00 40 00 00 02 72 00 39 00 00 00 00 00 60 70 12 00 00 ab 21 00 0a 6e 04 b0 00 1e 02 58 02 58 01 55 01 d2 00 0a 01 88 00 32 00 0d 03 97 11 48 08 00 0c 00 07 10 20 00 06 0f 0f 33 0e 1c 2a 38 46 54 62 69 70 77 79 7b 7d 7e 00 82 11 40 19 c0 22 3e 32 7c 3a ba 3a f8 3b 38 3b 38 3b 76 4b 76 4b 74 4b 74 5b b4 73 f4 01 00 00 00 00 00 00 39 00 00 40 00 00 03 f0 aa 10 39 00 00 40 00 00 0e bd 10 02 31 46 75 8a b9 01 32 45 76 89 ba 39 00 00 40 00 00 03 f0 aa 17 15 00 00 40 00 00 02 b0 11 39 00 00 40 00 00 07 c0 21 00 34 20 31 04 15 00 00 40 00 00 02 65 06 15 00 00 40 00 00 02 bf ff 39 00 00 40 00 00 03 ff 5a 80 15 00 00 40 00 00 02 65 0a 39 00 00 40 00 00 03 f9 9e 8f 15 00 00 40 00 00 02 65 0f 15 00 00 40 00 00 02 f9 14 39 00 00 40 00 00 03 ff 5a 81 15 00 00 40 00 00 02 65 03 15 00 00 40 00 00 02 f3 24 15 00 00 40 00 00 02 65 05 15 00 00 40 00 00 02 f3 a0 39 00 00 40 00 00 03 ff 5a 81 15 00 00 40 00 00 02 65 02 39 00 00 40 00 00 05 fb d3 d3 d3 d3 39 00 00 40 00 00 03 f0 aa 10 15 00 00 40 00 00 02 65 04 15 00 00 00 00 00 02 cf 4b 39 00 00 40 00 00 03 f0 aa 10 15 00 00 40 00 00 02 65 01 15 00 00 00 00 00 02 cf 07 39 00 00 40 00 00 03 f0 aa 10 15 00 00 40 00 00 02 65 03 15 00 00 00 00 00 02 cf 24 39 00 00 40 00 00 03 f0 aa 10 15 00 00 40 00 00 02 b6 00 39 00 00 40 00 00 03 ff 5a 82 15 00 00 40 00 00 02 65 04 15 00 00 00 00 00 02 f8 10 39 00 00 40 00 00 03 f0 aa 11 15 00 00 40 00 00 02 c0 00 15 00 00 40 00 00 02 65 09 39 00 00 40 00 00 04 c0 55 aa aa 39 00 00 40 00 00 0c c1 03 34 03 99 03 34 03 ff ff a6 00 15 00 00 40 00 00 02 55 01 39 00 00 40 00 00 03 f0 aa 10 15 00 00 40 00 00 02 65 07 15 00 00 40 00 00 02 d0 00 15 00 00 40 00 00 02 65 09 39 00 00 40 00 00 03 d0 03 19 15 00 00 40 00 00 02 65 0c 15 00 00 40 00 00 02 d0 00 15 00 00 40 00 00 02 65 0e 39 00 00 40 00 00 03 d0 03 19 15 00 00 40 00 00 02 65 11 15 00 00 40 00 00 02 d0 19 39 00 00 40 00 00 03 f0 aa 12 15 00 00 40 00 00 02 65 0b 15 00 00 40 00 00 02 d2 10 39 00 00 40 00 00 03 f0 aa 10 39 00 00 00 00 00 09 c4 34 34 34 34 34 34 34 34 39 00 00 40 00 00 03 f0 aa 12 15 00 00 40 00 00 02 d6 00 15 00 00 40 00 00 02 65 02 15 00 00 00 00 00 02 d1 00 39 00 00 40 00 00 03 5f 04 7e 39 00 00 40 00 00 03 f0 aa 12 39 00 00 40 00 00 20 c3 e1 20 30 01 cd 01 cd 01 cd 01 cd 01 cd 01 cd 01 cd 00 64 00 64 00 64 00 64 00 64 00 64 00 64 39 00 00 40 00 00 03 ff 5a 81 15 00 00 40 00 00 02 65 15 15 00 00 00 00 00 02 fc 7e 05 00 00 00 78 00 01 11 05 00 00 00 00 00 01 29];
			qcom,dsi-mode-te-width-us = <3100>;
			mi,mdss-dc-status-control-dc-6C-cfg = <0x03 0x01>;
			qcom,mdss-dsi-h-sync-skew = <0x00>;
			qcom,mdss-dsi-panel-framerate = <0x5a>;
			cell-index = <0x08>;
			qcom,src-chroma-format = <0x01>;
			qcom,mdss-dsc-block-prediction-enable;
			qcom,mdss-dsc-bit-per-pixel = <0x08>;
			qcom,mdss-dsc-bit-per-component = <0x0a>;
			qcom,mdss-dsc-slice-per-pkt = <0x02>;
			qcom,mdss-dsc-slice-width = <0x258>;
			qcom,mdss-dsc-slice-height = <0x1e>;
			qcom,mdss-dsc-scr-version = <0x00>;
			qcom,mdss-dsc-version = <0x12>;
			qcom,compression-mode = "dsc";
			qcom,default-topology-index = <0x00>;
			qcom,display-topology = <0x02 0x02 0x01>;
			qcom,mdss-dsi-panel-phy-timings = [00 26 0a 0a 1b 19 0a 0a 0a 02 04 00 20 0f];
			qcom,mdss-mdp-transfer-time-us = <7300>;
			qcom,mdss-dsi-panel-jitter = <0x05 0x01>;
			qcom,mdss-dsi-panel-clockrate = <0x448b9b80>;
			qcom,mdss-dsi-v-bottom-border = <0x00>;
			qcom,mdss-dsi-v-top-border = <0x00>;
			qcom,mdss-dsi-h-right-border = <0x00>;
			qcom,mdss-dsi-h-left-border = <0x00>;
			qcom,mdss-dsi-h-sync-pulse = <0x00>;
			qcom,mdss-dsi-v-pulse-width = <0x08>;
			qcom,mdss-dsi-v-front-porch = <0x2d>;
			qcom,mdss-dsi-v-back-porch = <0x25>;
			qcom,mdss-dsi-h-pulse-width = <0x10>;
			qcom,mdss-dsi-h-back-porch = <0x20>;
			qcom,mdss-dsi-h-front-porch = <0x10>;
			qcom,mdss-dsi-panel-height = <0xa6e>;
			qcom,mdss-dsi-panel-width = <0x4b0>;
			mi,mdss-dsi-dimmingoff-command-state = "dsi_hs_mode";
			mi,mdss-dsi-dimmingoff-command = [15 00 00 00 00 00 02 53 20];
			mi,mdss-dsi-dimmingon-command-state = "dsi_hs_mode";
			mi,mdss-dsi-dimmingon-command = [15 00 00 00 00 00 02 53 28];
			mi,mdss-dsi-auto-current-limit-command-update = <0xc1 0x01 0x02>;
			mi,mdss-dsi-auto-current-limit-command-state = "dsi_lp_mode";
			mi,mdss-dsi-auto-current-limit-command = <0x39000040 0x3f0 0xaa113900 0x00 0x3c103ff>;
			mi,mdss-dsi-round-corner-off-command-state = "dsi_lp_mode";
			mi,mdss-dsi-round-corner-off-command = [39 00 00 40 00 00 03 f0 aa 18 15 00 00 00 00 00 02 b0 00];
			mi,mdss-dsi-round-corner-on-command-state = "dsi_lp_mode";
			mi,mdss-dsi-round-corner-on-command = [39 00 00 40 00 00 03 f0 aa 18 15 00 00 00 00 00 02 b0 80];
			mi,mdss-dsi-doze-lbm-nolp-command-state = "dsi_lp_mode";
			mi,mdss-dsi-doze-hbm-nolp-command-state = "dsi_lp_mode";
			mi,mdss-dsi-doze-lbm-nolp-command = [05 00 00 40 00 00 01 38 15 00 00 40 00 00 02 75 00 39 00 00 40 00 00 03 f0 aa 1b 15 00 00 40 00 00 02 d0 00 39 00 00 40 00 00 03 51 00 14 39 00 00 40 00 00 03 f0 aa 10 15 00 00 00 00 00 02 cf 16];
			mi,mdss-dsi-doze-hbm-nolp-command = [05 00 00 40 00 00 01 38 15 00 00 40 00 00 02 75 00 39 00 00 40 00 00 03 f0 aa 1b 15 00 00 40 00 00 02 d0 00 39 00 00 40 00 00 03 51 00 ee 39 00 00 40 00 00 03 f0 aa 10 15 00 00 00 00 00 02 cf 16];
			mi,mdss-dsi-doze-lbm-command-state = "dsi_lp_mode";
			mi,mdss-dsi-doze-lbm-command = [39 00 00 40 00 00 03 f0 aa 1b 15 00 00 40 00 00 02 d0 00 15 00 00 40 00 00 02 75 00 15 00 00 00 09 00 02 71 00 39 00 00 40 00 00 03 f0 aa 1b 39 00 00 40 00 00 0e d2 04 01 03 04 0b 0b 0b 0b 0b 00 0e e0 00 15 00 00 40 00 00 02 d0 11 05 00 00 40 00 00 01 39 15 00 00 40 00 00 02 6d 02 15 00 00 40 00 00 02 75 01 39 00 00 40 00 00 03 f0 aa 10 15 00 00 40 00 00 02 cf 09 15 00 00 40 00 00 02 53 20 39 00 00 00 00 00 03 51 00 12];
			mi,mdss-dsi-doze-hbm-command-state = "dsi_lp_mode";
			mi,mdss-dsi-doze-hbm-command = [39 00 00 40 00 00 03 f0 aa 1b 15 00 00 40 00 00 02 d0 00 15 00 00 40 00 00 02 75 00 15 00 00 00 09 00 02 71 00 39 00 00 40 00 00 03 f0 aa 1b 39 00 00 40 00 00 0e d2 04 01 03 04 0b 0b 0b 0b 0b 00 0e e0 00 15 00 00 40 00 00 02 d0 11 05 00 00 40 00 00 01 39 15 00 00 40 00 00 02 6d 00 15 00 00 40 00 00 02 75 01 39 00 00 40 00 00 03 f0 aa 10 15 00 00 40 00 00 02 cf 09 15 00 00 40 00 00 02 53 20 39 00 00 00 00 00 03 51 00 cf];
			mi,mdss-dsi-hbm-off-command-state = "dsi_hs_mode";
			mi,mdss-dsi-hbm-off-command = [39 00 00 40 00 00 03 f0 aa 10 15 00 00 40 00 00 02 65 01 15 00 00 40 00 00 02 d0 04 39 00 00 00 00 00 03 51 0a ab];
			mi,mdss-dsi-hbm-on-command-state = "dsi_hs_mode";
			mi,mdss-dsi-hbm-on-command = [39 00 00 40 00 00 03 f0 aa 10 15 00 00 40 00 00 02 65 01 15 00 00 40 00 00 02 d0 05 39 00 00 00 00 00 03 51 17 ff];
			mi,mdss-dsi-vint-off-command-state = "dsi_lp_mode";
			mi,mdss-dsi-vint-off-command = [39 00 00 40 00 00 03 f0 aa 12 39 00 00 40 00 00 02 bf 63 39 00 00 40 00 00 02 65 30 39 00 00 40 00 00 02 bf 63 39 00 00 40 00 00 02 d9 63 39 00 00 40 00 00 02 65 30 39 00 00 40 00 00 02 d9 63 39 00 00 40 00 00 02 df 63 39 00 00 40 00 00 02 65 30 39 00 00 40 00 00 02 df 63 39 00 00 40 00 00 02 eb 63 39 00 00 40 00 00 02 65 30 39 00 00 00 00 00 02 eb 63];
			qcom,mdss-dsi-off-command-state = "dsi_hs_mode";
			qcom,mdss-dsi-off-command = <0x5000000 0x128 0x5000000 0x78000110>;
		};

		timing@auto_120_to_10hz_index_09 {
			mi,mdss-dsi-dc-off-command-state = "dsi_lp_mode";
			mi,mdss-dsi-dc-off-command = [15 00 00 00 00 00 02 6c 00];
			mi,mdss-dsi-dc-on-command-state = "dsi_lp_mode";
			mi,mdss-dsi-dc-on-command = [15 00 00 00 00 00 02 6c 02];
			qcom,mdss-dsi-nolp-command-state = "dsi_lp_mode";
			qcom,mdss-dsi-nolp-command-update = <0x51 0x0b 0x02 0x6c 0x01 0x01>;
			qcom,mdss-dsi-nolp-command = <0x5000040 0x138 0x15000040 0x26c 0x2150000 0x40000002 0x71001500 0x400000 0x2750139 0x4000 0x3f0aa 0x1b150000 0x40000002 0x650c3900 0x400000 0x5d50b0b 0xb0b1500 0x400000 0x2650c39 0x4000 0x5d70b 0xb0b0b39 0x4000 0xed202 0x103040b 0x7090b00 0x00 0x15000040 0x2d0 0x11390000 0x40000003 0x51000039 0x4000 0x3f0aa 0x10150000 0x90002 0xcf093900 0x00 0x3f0aa00>;
			qcom,mdss-dsi-timing-switch-command-state = "dsi_lp_mode";
			qcom,mdss-dsi-timing-switch-command = [15 00 00 40 00 00 02 71 00 15 00 00 40 00 00 02 75 01 39 00 00 40 00 00 03 f0 aa 1b 15 00 00 40 00 00 02 65 0c 39 00 00 40 00 00 05 d5 0b 0b 0b 0b 15 00 00 40 00 00 02 65 0c 39 00 00 40 00 00 05 d7 0b 0b 0b 0b 39 00 00 40 00 00 0e d2 02 01 03 04 0b 07 09 0b 00 00 00 00 00 15 00 00 40 00 00 02 d0 11 39 00 00 40 00 00 03 f0 aa 10 15 00 00 00 00 00 02 cf 09];
			mi,mdss-dsi-timing-switch-from-normal-mode-command-state = "dsi_lp_mode";
			mi,mdss-dsi-timing-switch-from-normal-mode-command-update = <0x6c 0x00 0x01>;
			mi,mdss-dsi-timing-switch-from-normal-mode-command = [15 00 00 00 00 00 02 6c 00];
			mi,mdss-dsi-timing-switch-from-skip-mode-command-state = "dsi_lp_mode";
			mi,mdss-dsi-timing-switch-from-skip-mode-command-update = <0x6c 0x01 0x01>;
			mi,mdss-dsi-timing-switch-from-skip-mode-command = [15 00 00 40 00 00 02 71 00 15 00 00 00 0a 00 02 6c 00];
			mi,mdss-dsi-timing-switch-from-auto-mode-command-state = "dsi_lp_mode";
			mi,mdss-dsi-timing-switch-from-auto-mode-command-update = <0x6c 0x01 0x01>;
			mi,mdss-dsi-timing-switch-from-auto-mode-command = [15 00 00 40 00 00 02 71 00 15 00 00 40 00 00 02 6c 02 39 00 00 40 00 00 03 f0 aa 1b 15 00 00 40 00 00 02 d0 00 15 00 00 00 0a 00 02 75 00];
			qcom,mdss-dsi-on-command-state = "dsi_lp_mode";
			qcom,mdss-dsi-on-command = [39 00 00 40 00 00 03 f0 aa 10 15 00 00 40 00 00 02 65 01 15 00 00 40 00 00 02 d0 05 15 00 00 40 00 00 02 03 01 15 00 00 40 00 00 02 35 00 15 00 00 40 00 00 02 53 28 39 00 00 40 00 00 03 f0 aa 13 15 00 00 40 00 00 02 c8 10 15 00 00 40 00 00 02 d0 10 15 00 00 40 00 00 02 e0 10 15 00 00 40 00 00 02 e8 10 39 00 00 40 00 00 03 51 00 00 15 00 00 40 00 00 02 5e 00 15 00 00 40 00 00 02 59 09 39 00 00 40 00 00 03 ff 5a 81 15 00 00 40 00 00 02 65 1b 15 00 00 40 00 00 02 f8 04 15 00 00 40 00 00 02 65 1a 15 00 00 40 00 00 02 f8 0f 15 00 00 40 00 00 02 65 0a 15 00 00 00 00 00 02 f8 fb 15 00 00 40 00 00 02 6c 02 15 00 00 40 00 00 02 71 00 15 00 00 40 00 00 02 75 01 39 00 00 40 00 00 03 f0 aa 1b 15 00 00 40 00 00 02 65 0c 39 00 00 40 00 00 05 d5 0b 0b 0b 0b 15 00 00 40 00 00 02 65 0c 39 00 00 40 00 00 05 d7 0b 0b 0b 0b 39 00 00 40 00 00 0e d2 02 01 03 04 0b 07 09 0b 00 00 00 00 00 15 00 00 40 00 00 02 d0 11 39 00 00 40 00 00 03 f0 aa 10 15 00 00 00 00 00 02 cf 09 15 00 00 40 00 00 02 6d 00 15 00 00 40 00 00 02 6f 02 15 00 00 40 00 00 02 72 00 39 00 00 00 00 00 60 70 12 00 00 ab 21 00 0a 6e 04 b0 00 1e 02 58 02 58 01 55 01 d2 00 0a 01 88 00 32 00 0d 03 97 11 48 08 00 0c 00 07 10 20 00 06 0f 0f 33 0e 1c 2a 38 46 54 62 69 70 77 79 7b 7d 7e 00 82 11 40 19 c0 22 3e 32 7c 3a ba 3a f8 3b 38 3b 38 3b 76 4b 76 4b 74 4b 74 5b b4 73 f4 01 00 00 00 00 00 00 39 00 00 40 00 00 03 f0 aa 10 39 00 00 40 00 00 0e bd 10 02 31 46 75 8a b9 01 32 45 76 89 ba 39 00 00 40 00 00 03 f0 aa 17 15 00 00 40 00 00 02 b0 11 39 00 00 40 00 00 07 c0 21 00 34 20 31 04 15 00 00 40 00 00 02 65 06 15 00 00 40 00 00 02 bf ff 39 00 00 40 00 00 03 ff 5a 80 15 00 00 40 00 00 02 65 0a 39 00 00 40 00 00 03 f9 9e 8f 15 00 00 40 00 00 02 65 0f 15 00 00 40 00 00 02 f9 14 39 00 00 40 00 00 03 ff 5a 81 15 00 00 40 00 00 02 65 03 15 00 00 40 00 00 02 f3 24 15 00 00 40 00 00 02 65 05 15 00 00 40 00 00 02 f3 a0 39 00 00 40 00 00 03 ff 5a 81 15 00 00 40 00 00 02 65 02 39 00 00 40 00 00 05 fb d3 d3 d3 d3 39 00 00 40 00 00 03 f0 aa 10 15 00 00 40 00 00 02 65 04 15 00 00 00 00 00 02 cf 4b 39 00 00 40 00 00 03 f0 aa 10 15 00 00 40 00 00 02 65 01 15 00 00 00 00 00 02 cf 07 39 00 00 40 00 00 03 f0 aa 10 15 00 00 40 00 00 02 65 03 15 00 00 00 00 00 02 cf 24 39 00 00 40 00 00 03 f0 aa 10 15 00 00 40 00 00 02 b6 00 39 00 00 40 00 00 03 ff 5a 82 15 00 00 40 00 00 02 65 04 15 00 00 00 00 00 02 f8 10 39 00 00 40 00 00 03 f0 aa 11 15 00 00 40 00 00 02 c0 00 15 00 00 40 00 00 02 65 09 39 00 00 40 00 00 04 c0 55 aa aa 39 00 00 40 00 00 0c c1 03 34 03 99 03 34 03 ff ff a6 00 15 00 00 40 00 00 02 55 01 39 00 00 40 00 00 03 f0 aa 10 15 00 00 40 00 00 02 65 07 15 00 00 40 00 00 02 d0 00 15 00 00 40 00 00 02 65 09 39 00 00 40 00 00 03 d0 03 19 15 00 00 40 00 00 02 65 0c 15 00 00 40 00 00 02 d0 00 15 00 00 40 00 00 02 65 0e 39 00 00 40 00 00 03 d0 03 19 15 00 00 40 00 00 02 65 11 15 00 00 40 00 00 02 d0 19 39 00 00 40 00 00 03 f0 aa 12 15 00 00 40 00 00 02 65 0b 15 00 00 40 00 00 02 d2 10 39 00 00 40 00 00 03 f0 aa 10 39 00 00 00 00 00 09 c4 34 34 34 34 34 34 34 34 39 00 00 40 00 00 03 f0 aa 12 15 00 00 40 00 00 02 d6 00 15 00 00 40 00 00 02 65 02 15 00 00 00 00 00 02 d1 00 39 00 00 40 00 00 03 5f 04 7e 39 00 00 40 00 00 03 f0 aa 12 39 00 00 40 00 00 20 c3 e1 20 30 01 cd 01 cd 01 cd 01 cd 01 cd 01 cd 01 cd 00 64 00 64 00 64 00 64 00 64 00 64 00 64 39 00 00 40 00 00 03 ff 5a 81 15 00 00 40 00 00 02 65 15 15 00 00 00 00 00 02 fc 7e 05 00 00 00 78 00 01 11 05 00 00 00 00 00 01 29];
			qcom,dsi-mode-te-width-us = <245>;
			mi,mdss-dc-status-control-dc-6C-cfg = <0x02 0x00>;
			mi,mdss-dsi-ddic-min-framerate = <0x0a>;
			mi,mdss-dsi-sf-framerate = <0x78>;
			mi,mdss-dsi-ddic-mode = "auto";
			qcom,mdss-dsi-h-sync-skew = <0xbc0a>;
			qcom,mdss-dsi-panel-framerate = <0x78>;
			cell-index = <0x09>;
			qcom,src-chroma-format = <0x01>;
			qcom,mdss-dsc-block-prediction-enable;
			qcom,mdss-dsc-bit-per-pixel = <0x08>;
			qcom,mdss-dsc-bit-per-component = <0x0a>;
			qcom,mdss-dsc-slice-per-pkt = <0x02>;
			qcom,mdss-dsc-slice-width = <0x258>;
			qcom,mdss-dsc-slice-height = <0x1e>;
			qcom,mdss-dsc-scr-version = <0x00>;
			qcom,mdss-dsc-version = <0x12>;
			qcom,compression-mode = "dsc";
			qcom,default-topology-index = <0x00>;
			qcom,display-topology = <0x02 0x02 0x01>;
			qcom,mdss-dsi-panel-phy-timings = [00 26 0a 0a 1b 19 0a 0a 0a 02 04 00 20 0f];
			qcom,mdss-mdp-transfer-time-us = <7300>;
			qcom,mdss-dsi-panel-jitter = <0x05 0x01>;
			qcom,mdss-dsi-panel-clockrate = <0x448b9b80>;
			qcom,mdss-dsi-v-bottom-border = <0x00>;
			qcom,mdss-dsi-v-top-border = <0x00>;
			qcom,mdss-dsi-h-right-border = <0x00>;
			qcom,mdss-dsi-h-left-border = <0x00>;
			qcom,mdss-dsi-h-sync-pulse = <0x00>;
			qcom,mdss-dsi-v-pulse-width = <0x08>;
			qcom,mdss-dsi-v-front-porch = <0x2d>;
			qcom,mdss-dsi-v-back-porch = <0x25>;
			qcom,mdss-dsi-h-pulse-width = <0x10>;
			qcom,mdss-dsi-h-back-porch = <0x20>;
			qcom,mdss-dsi-h-front-porch = <0x10>;
			qcom,mdss-dsi-panel-height = <0xa6e>;
			qcom,mdss-dsi-panel-width = <0x4b0>;
			mi,mdss-dsi-dimmingoff-command-state = "dsi_hs_mode";
			mi,mdss-dsi-dimmingoff-command = [15 00 00 00 00 00 02 53 20];
			mi,mdss-dsi-dimmingon-command-state = "dsi_hs_mode";
			mi,mdss-dsi-dimmingon-command = [15 00 00 00 00 00 02 53 28];
			mi,mdss-dsi-auto-current-limit-command-update = <0xc1 0x01 0x02>;
			mi,mdss-dsi-auto-current-limit-command-state = "dsi_lp_mode";
			mi,mdss-dsi-auto-current-limit-command = <0x39000040 0x3f0 0xaa113900 0x00 0x3c103ff>;
			mi,mdss-dsi-round-corner-off-command-state = "dsi_lp_mode";
			mi,mdss-dsi-round-corner-off-command = [39 00 00 40 00 00 03 f0 aa 18 15 00 00 00 00 00 02 b0 00];
			mi,mdss-dsi-round-corner-on-command-state = "dsi_lp_mode";
			mi,mdss-dsi-round-corner-on-command = [39 00 00 40 00 00 03 f0 aa 18 15 00 00 00 00 00 02 b0 80];
			mi,mdss-dsi-doze-lbm-nolp-command-state = "dsi_lp_mode";
			mi,mdss-dsi-doze-hbm-nolp-command-state = "dsi_lp_mode";
			mi,mdss-dsi-doze-lbm-nolp-command = [05 00 00 40 00 00 01 38 15 00 00 40 00 00 02 75 00 39 00 00 40 00 00 03 f0 aa 1b 15 00 00 40 00 00 02 d0 00 39 00 00 40 00 00 03 51 00 14 39 00 00 40 00 00 03 f0 aa 10 15 00 00 00 00 00 02 cf 16];
			mi,mdss-dsi-doze-hbm-nolp-command = [05 00 00 40 00 00 01 38 15 00 00 40 00 00 02 75 00 39 00 00 40 00 00 03 f0 aa 1b 15 00 00 40 00 00 02 d0 00 39 00 00 40 00 00 03 51 00 ee 39 00 00 40 00 00 03 f0 aa 10 15 00 00 00 00 00 02 cf 16];
			mi,mdss-dsi-doze-lbm-command-state = "dsi_lp_mode";
			mi,mdss-dsi-doze-lbm-command = [39 00 00 40 00 00 03 f0 aa 1b 15 00 00 40 00 00 02 d0 00 15 00 00 40 00 00 02 75 00 15 00 00 00 09 00 02 71 00 39 00 00 40 00 00 03 f0 aa 1b 39 00 00 40 00 00 0e d2 04 01 03 04 0b 0b 0b 0b 0b 00 0e e0 00 15 00 00 40 00 00 02 d0 11 05 00 00 40 00 00 01 39 15 00 00 40 00 00 02 6d 02 15 00 00 40 00 00 02 75 01 39 00 00 40 00 00 03 f0 aa 10 15 00 00 40 00 00 02 cf 09 15 00 00 40 00 00 02 53 20 39 00 00 00 00 00 03 51 00 12];
			mi,mdss-dsi-doze-hbm-command-state = "dsi_lp_mode";
			mi,mdss-dsi-doze-hbm-command = [39 00 00 40 00 00 03 f0 aa 1b 15 00 00 40 00 00 02 d0 00 15 00 00 40 00 00 02 75 00 15 00 00 00 09 00 02 71 00 39 00 00 40 00 00 03 f0 aa 1b 39 00 00 40 00 00 0e d2 04 01 03 04 0b 0b 0b 0b 0b 00 0e e0 00 15 00 00 40 00 00 02 d0 11 05 00 00 40 00 00 01 39 15 00 00 40 00 00 02 6d 00 15 00 00 40 00 00 02 75 01 39 00 00 40 00 00 03 f0 aa 10 15 00 00 40 00 00 02 cf 09 15 00 00 40 00 00 02 53 20 39 00 00 00 00 00 03 51 00 cf];
			mi,mdss-dsi-hbm-off-command-state = "dsi_hs_mode";
			mi,mdss-dsi-hbm-off-command = [39 00 00 40 00 00 03 f0 aa 10 15 00 00 40 00 00 02 65 01 15 00 00 40 00 00 02 d0 04 39 00 00 00 00 00 03 51 0a ab];
			mi,mdss-dsi-hbm-on-command-state = "dsi_hs_mode";
			mi,mdss-dsi-hbm-on-command = [39 00 00 40 00 00 03 f0 aa 10 15 00 00 40 00 00 02 65 01 15 00 00 40 00 00 02 d0 05 39 00 00 00 00 00 03 51 17 ff];
			mi,mdss-dsi-vint-off-command-state = "dsi_lp_mode";
			mi,mdss-dsi-vint-off-command = [39 00 00 40 00 00 03 f0 aa 12 39 00 00 40 00 00 02 bf 63 39 00 00 40 00 00 02 65 30 39 00 00 40 00 00 02 bf 63 39 00 00 40 00 00 02 d9 63 39 00 00 40 00 00 02 65 30 39 00 00 40 00 00 02 d9 63 39 00 00 40 00 00 02 df 63 39 00 00 40 00 00 02 65 30 39 00 00 40 00 00 02 df 63 39 00 00 40 00 00 02 eb 63 39 00 00 40 00 00 02 65 30 39 00 00 00 00 00 02 eb 63];
			qcom,mdss-dsi-off-command-state = "dsi_hs_mode";
			qcom,mdss-dsi-off-command = <0x5000000 0x128 0x5000000 0x78000110>;
		};

		timing@wqhd_test_120_to_0.5hz_index_11 {
			mi,mdss-dsi-dc-off-command-state = "dsi_lp_mode";
			mi,mdss-dsi-dc-off-command = [15 00 00 00 00 00 02 6c 00];
			mi,mdss-dsi-dc-on-command-state = "dsi_lp_mode";
			mi,mdss-dsi-dc-on-command = [15 00 00 00 00 00 02 6c 02];
			qcom,mdss-dsi-nolp-command-state = "dsi_lp_mode";
			qcom,mdss-dsi-nolp-command-update = <0x51 0x04 0x02 0x6c 0x07 0x01>;
			qcom,mdss-dsi-nolp-command = [05 00 00 40 00 00 01 38 15 00 00 40 00 00 02 75 00 39 00 00 40 00 00 03 f0 aa 1b 15 00 00 40 00 00 02 d0 00 39 00 00 40 00 00 03 51 00 00 39 00 00 40 00 00 03 f0 aa 10 15 00 00 00 09 00 02 cf 16 15 00 00 40 00 00 02 6c 02 15 00 00 40 00 00 02 71 00 15 00 00 40 00 00 02 75 01 39 00 00 40 00 00 03 f0 aa 1b 15 00 00 40 00 00 02 65 0c 39 00 00 40 00 00 05 d5 ef ef ef ef 39 00 00 40 00 00 0e d2 00 ef 04 03 05 07 09 0b 00 00 00 00 00 15 00 00 40 00 00 02 d0 11 39 00 00 40 00 00 03 f0 aa 10 15 00 00 40 00 00 02 cf 09 39 00 00 00 00 00 03 f0 aa 00];
			qcom,mdss-dsi-timing-switch-command-state = "dsi_lp_mode";
			qcom,mdss-dsi-timing-switch-command-update = <0x6c 0x00 0x01>;
			qcom,mdss-dsi-timing-switch-command = [15 00 00 40 00 00 02 6c 02 15 00 00 40 00 00 02 71 00 15 00 00 40 00 00 02 75 01 39 00 00 40 00 00 03 f0 aa 1b 15 00 00 40 00 00 02 65 0c 39 00 00 40 00 00 05 d5 ef ef ef ef 39 00 00 40 00 00 0e d2 00 ef 04 03 05 07 09 0b 00 00 00 00 00 15 00 00 40 00 00 02 d0 11 39 00 00 40 00 00 03 f0 aa 10 15 00 00 00 00 00 02 cf 09];
			qcom,mdss-dsi-on-command-state = "dsi_lp_mode";
			qcom,mdss-dsi-on-command = [39 00 00 40 00 00 03 f0 aa 10 15 00 00 40 00 00 02 65 01 15 00 00 40 00 00 02 d0 05 15 00 00 40 00 00 02 03 01 15 00 00 40 00 00 02 35 00 15 00 00 40 00 00 02 53 28 39 00 00 40 00 00 03 f0 aa 13 15 00 00 40 00 00 02 c8 10 15 00 00 40 00 00 02 d0 10 15 00 00 40 00 00 02 e0 10 15 00 00 40 00 00 02 e8 10 39 00 00 40 00 00 03 51 00 00 15 00 00 40 00 00 02 5e 00 15 00 00 40 00 00 02 59 09 39 00 00 40 00 00 03 ff 5a 81 15 00 00 40 00 00 02 65 1b 15 00 00 40 00 00 02 f8 04 15 00 00 40 00 00 02 65 1a 15 00 00 40 00 00 02 f8 0f 15 00 00 40 00 00 02 65 0a 15 00 00 00 00 00 02 f8 fb 15 00 00 40 00 00 02 6c 02 15 00 00 40 00 00 02 71 00 15 00 00 40 00 00 02 75 01 39 00 00 40 00 00 03 f0 aa 1b 15 00 00 40 00 00 02 65 0c 39 00 00 40 00 00 05 d5 ef ef ef ef 39 00 00 40 00 00 0e d2 00 ef 04 03 05 07 09 0b 00 00 00 00 00 15 00 00 40 00 00 02 d0 11 39 00 00 40 00 00 03 f0 aa 10 15 00 00 00 00 00 02 cf 09 15 00 00 40 00 00 02 6d 00 15 00 00 40 00 00 02 6f 02 15 00 00 40 00 00 02 72 00 39 00 00 00 00 00 60 70 12 00 00 ab 21 00 0a 6e 04 b0 00 1e 02 58 02 58 01 55 01 d2 00 0a 01 88 00 32 00 0d 03 97 11 48 08 00 0c 00 07 10 20 00 06 0f 0f 33 0e 1c 2a 38 46 54 62 69 70 77 79 7b 7d 7e 00 82 11 40 19 c0 22 3e 32 7c 3a ba 3a f8 3b 38 3b 38 3b 76 4b 76 4b 74 4b 74 5b b4 73 f4 01 00 00 00 00 00 00 39 00 00 40 00 00 03 f0 aa 10 39 00 00 40 00 00 0e bd 10 02 31 46 75 8a b9 01 32 45 76 89 ba 39 00 00 40 00 00 03 f0 aa 17 15 00 00 40 00 00 02 b0 11 39 00 00 40 00 00 07 c0 21 00 34 20 31 04 15 00 00 40 00 00 02 65 06 15 00 00 40 00 00 02 bf ff 39 00 00 40 00 00 03 ff 5a 80 15 00 00 40 00 00 02 65 0a 39 00 00 40 00 00 03 f9 9e 8f 15 00 00 40 00 00 02 65 0f 15 00 00 40 00 00 02 f9 14 39 00 00 40 00 00 03 ff 5a 81 15 00 00 40 00 00 02 65 03 15 00 00 40 00 00 02 f3 24 15 00 00 40 00 00 02 65 05 15 00 00 40 00 00 02 f3 a0 39 00 00 40 00 00 03 ff 5a 81 15 00 00 40 00 00 02 65 02 39 00 00 40 00 00 05 fb d3 d3 d3 d3 39 00 00 40 00 00 03 f0 aa 10 15 00 00 40 00 00 02 65 04 15 00 00 00 00 00 02 cf 4b 39 00 00 40 00 00 03 f0 aa 10 15 00 00 40 00 00 02 65 01 15 00 00 00 00 00 02 cf 07 39 00 00 40 00 00 03 f0 aa 10 15 00 00 40 00 00 02 65 03 15 00 00 00 00 00 02 cf 24 39 00 00 40 00 00 03 f0 aa 10 15 00 00 40 00 00 02 b6 00 39 00 00 40 00 00 03 ff 5a 82 15 00 00 40 00 00 02 65 04 15 00 00 00 00 00 02 f8 10 39 00 00 40 00 00 03 f0 aa 11 15 00 00 40 00 00 02 c0 00 15 00 00 40 00 00 02 65 09 39 00 00 40 00 00 04 c0 55 aa aa 39 00 00 40 00 00 0c c1 03 34 03 99 03 34 03 ff ff a6 00 15 00 00 40 00 00 02 55 01 39 00 00 40 00 00 03 f0 aa 10 15 00 00 40 00 00 02 65 07 15 00 00 40 00 00 02 d0 00 15 00 00 40 00 00 02 65 09 39 00 00 40 00 00 03 d0 03 19 15 00 00 40 00 00 02 65 0c 15 00 00 40 00 00 02 d0 00 15 00 00 40 00 00 02 65 0e 39 00 00 40 00 00 03 d0 03 19 15 00 00 40 00 00 02 65 11 15 00 00 40 00 00 02 d0 19 39 00 00 40 00 00 03 f0 aa 12 15 00 00 40 00 00 02 65 0b 15 00 00 40 00 00 02 d2 10 39 00 00 40 00 00 03 f0 aa 10 39 00 00 00 00 00 09 c4 34 34 34 34 34 34 34 34 39 00 00 40 00 00 03 f0 aa 12 15 00 00 40 00 00 02 d6 00 15 00 00 40 00 00 02 65 02 15 00 00 00 00 00 02 d1 00 39 00 00 40 00 00 03 5f 04 7e 39 00 00 40 00 00 03 f0 aa 12 39 00 00 40 00 00 20 c3 e1 20 30 01 cd 01 cd 01 cd 01 cd 01 cd 01 cd 01 cd 00 64 00 64 00 64 00 64 00 64 00 64 00 64 39 00 00 40 00 00 03 ff 5a 81 15 00 00 40 00 00 02 65 15 15 00 00 00 00 00 02 fc 7e 05 00 00 00 78 00 01 11 05 00 00 00 00 00 01 29];
			mi,mdss-dc-status-control-dc-6C-cfg = <0x02 0x00>;
			mi,mdss-dsi-ddic-min-framerate = <0x7f>;
			mi,mdss-dsi-sf-framerate = <0x78>;
			mi,mdss-dsi-ddic-mode = "test";
			qcom,mdss-dsi-h-sync-skew = <0x7c7f>;
			qcom,mdss-dsi-panel-framerate = <0x78>;
			cell-index = <0x0b>;
			qcom,src-chroma-format = <0x01>;
			qcom,mdss-dsc-block-prediction-enable;
			qcom,mdss-dsc-bit-per-pixel = <0x08>;
			qcom,mdss-dsc-bit-per-component = <0x0a>;
			qcom,mdss-dsc-slice-per-pkt = <0x02>;
			qcom,mdss-dsc-slice-width = <0x258>;
			qcom,mdss-dsc-slice-height = <0x1e>;
			qcom,mdss-dsc-scr-version = <0x00>;
			qcom,mdss-dsc-version = <0x12>;
			qcom,compression-mode = "dsc";
			qcom,default-topology-index = <0x00>;
			qcom,display-topology = <0x02 0x02 0x01>;
			qcom,mdss-dsi-panel-phy-timings = [00 26 0a 0a 1b 19 0a 0a 0a 02 04 00 20 0f];
			qcom,mdss-mdp-transfer-time-us = <7300>;
			qcom,mdss-dsi-panel-jitter = <0x05 0x01>;
			qcom,mdss-dsi-panel-clockrate = <0x448b9b80>;
			qcom,mdss-dsi-v-bottom-border = <0x00>;
			qcom,mdss-dsi-v-top-border = <0x00>;
			qcom,mdss-dsi-h-right-border = <0x00>;
			qcom,mdss-dsi-h-left-border = <0x00>;
			qcom,mdss-dsi-h-sync-pulse = <0x00>;
			qcom,mdss-dsi-v-pulse-width = <0x08>;
			qcom,mdss-dsi-v-front-porch = <0x2d>;
			qcom,mdss-dsi-v-back-porch = <0x25>;
			qcom,mdss-dsi-h-pulse-width = <0x10>;
			qcom,mdss-dsi-h-back-porch = <0x20>;
			qcom,mdss-dsi-h-front-porch = <0x10>;
			qcom,mdss-dsi-panel-height = <0xa6e>;
			qcom,mdss-dsi-panel-width = <0x4b0>;
			mi,mdss-dsi-dimmingoff-command-state = "dsi_hs_mode";
			mi,mdss-dsi-dimmingoff-command = [15 00 00 00 00 00 02 53 20];
			mi,mdss-dsi-dimmingon-command-state = "dsi_hs_mode";
			mi,mdss-dsi-dimmingon-command = [15 00 00 00 00 00 02 53 28];
			mi,mdss-dsi-auto-current-limit-command-update = <0xc1 0x01 0x02>;
			mi,mdss-dsi-auto-current-limit-command-state = "dsi_lp_mode";
			mi,mdss-dsi-auto-current-limit-command = <0x39000040 0x3f0 0xaa113900 0x00 0x3c103ff>;
			mi,mdss-dsi-round-corner-off-command-state = "dsi_lp_mode";
			mi,mdss-dsi-round-corner-off-command = [39 00 00 40 00 00 03 f0 aa 18 15 00 00 00 00 00 02 b0 00];
			mi,mdss-dsi-round-corner-on-command-state = "dsi_lp_mode";
			mi,mdss-dsi-round-corner-on-command = [39 00 00 40 00 00 03 f0 aa 18 15 00 00 00 00 00 02 b0 80];
			mi,mdss-dsi-doze-lbm-nolp-command-state = "dsi_lp_mode";
			mi,mdss-dsi-doze-hbm-nolp-command-state = "dsi_lp_mode";
			mi,mdss-dsi-doze-lbm-nolp-command = [05 00 00 40 00 00 01 38 15 00 00 40 00 00 02 75 00 39 00 00 40 00 00 03 f0 aa 1b 15 00 00 40 00 00 02 d0 00 39 00 00 40 00 00 03 51 00 14 39 00 00 40 00 00 03 f0 aa 10 15 00 00 00 00 00 02 cf 16];
			mi,mdss-dsi-doze-hbm-nolp-command = [05 00 00 40 00 00 01 38 15 00 00 40 00 00 02 75 00 39 00 00 40 00 00 03 f0 aa 1b 15 00 00 40 00 00 02 d0 00 39 00 00 40 00 00 03 51 00 ee 39 00 00 40 00 00 03 f0 aa 10 15 00 00 00 00 00 02 cf 16];
			mi,mdss-dsi-doze-lbm-command-state = "dsi_lp_mode";
			mi,mdss-dsi-doze-lbm-command = [39 00 00 40 00 00 03 f0 aa 1b 15 00 00 40 00 00 02 d0 00 15 00 00 40 00 00 02 75 00 15 00 00 00 09 00 02 71 00 39 00 00 40 00 00 03 f0 aa 1b 39 00 00 40 00 00 0e d2 04 01 03 04 0b 0b 0b 0b 0b 00 0e e0 00 15 00 00 40 00 00 02 d0 11 05 00 00 40 00 00 01 39 15 00 00 40 00 00 02 6d 02 15 00 00 40 00 00 02 75 01 39 00 00 40 00 00 03 f0 aa 10 15 00 00 40 00 00 02 cf 09 15 00 00 40 00 00 02 53 20 39 00 00 00 00 00 03 51 00 12];
			mi,mdss-dsi-doze-hbm-command-state = "dsi_lp_mode";
			mi,mdss-dsi-doze-hbm-command = [39 00 00 40 00 00 03 f0 aa 1b 15 00 00 40 00 00 02 d0 00 15 00 00 40 00 00 02 75 00 15 00 00 00 09 00 02 71 00 39 00 00 40 00 00 03 f0 aa 1b 39 00 00 40 00 00 0e d2 04 01 03 04 0b 0b 0b 0b 0b 00 0e e0 00 15 00 00 40 00 00 02 d0 11 05 00 00 40 00 00 01 39 15 00 00 40 00 00 02 6d 00 15 00 00 40 00 00 02 75 01 39 00 00 40 00 00 03 f0 aa 10 15 00 00 40 00 00 02 cf 09 15 00 00 40 00 00 02 53 20 39 00 00 00 00 00 03 51 00 cf];
			mi,mdss-dsi-hbm-off-command-state = "dsi_hs_mode";
			mi,mdss-dsi-hbm-off-command = [39 00 00 40 00 00 03 f0 aa 10 15 00 00 40 00 00 02 65 01 15 00 00 40 00 00 02 d0 04 39 00 00 00 00 00 03 51 0a ab];
			mi,mdss-dsi-hbm-on-command-state = "dsi_hs_mode";
			mi,mdss-dsi-hbm-on-command = [39 00 00 40 00 00 03 f0 aa 10 15 00 00 40 00 00 02 65 01 15 00 00 40 00 00 02 d0 05 39 00 00 00 00 00 03 51 17 ff];
			mi,mdss-dsi-vint-off-command-state = "dsi_lp_mode";
			mi,mdss-dsi-vint-off-command = [39 00 00 40 00 00 03 f0 aa 12 39 00 00 40 00 00 02 bf 63 39 00 00 40 00 00 02 65 30 39 00 00 40 00 00 02 bf 63 39 00 00 40 00 00 02 d9 63 39 00 00 40 00 00 02 65 30 39 00 00 40 00 00 02 d9 63 39 00 00 40 00 00 02 df 63 39 00 00 40 00 00 02 65 30 39 00 00 40 00 00 02 df 63 39 00 00 40 00 00 02 eb 63 39 00 00 40 00 00 02 65 30 39 00 00 00 00 00 02 eb 63];
			qcom,mdss-dsi-off-command-state = "dsi_hs_mode";
			qcom,mdss-dsi-off-command = <0x5000000 0x128 0x5000000 0x78000110>;
		};
	};
};
